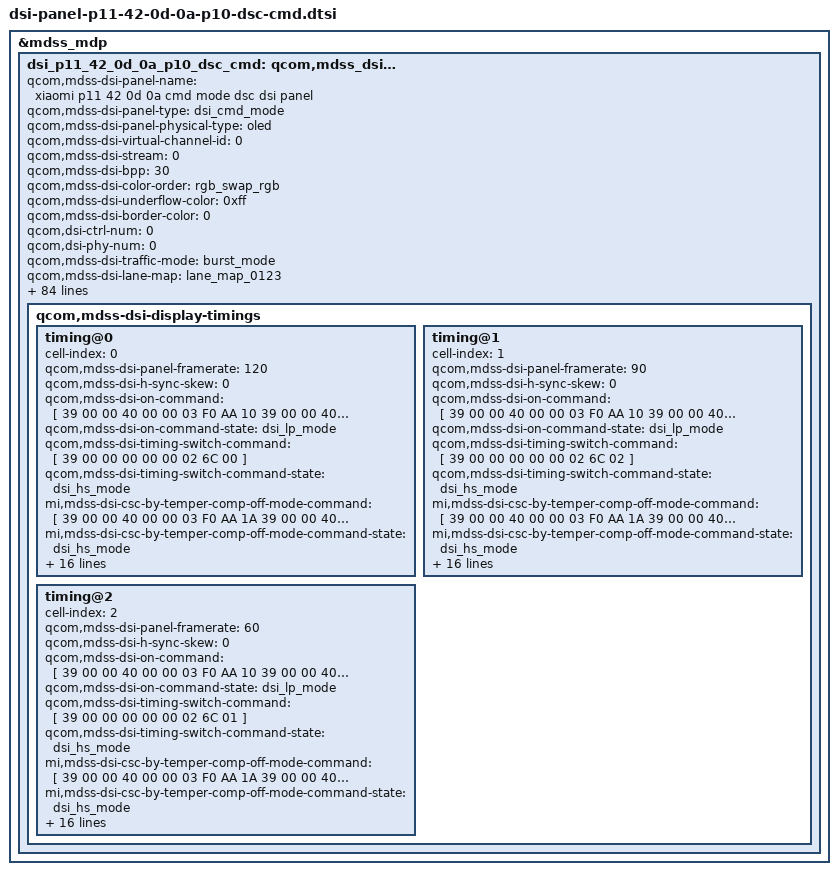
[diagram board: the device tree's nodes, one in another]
&mdss_mdp {
	dsi_p11_42_0d_0a_p10_dsc_cmd: qcom,mdss_dsi_p11_42_0d_0a_p10_dsc_cmd {
		qcom,mdss-dsi-panel-name = "xiaomi p11 42 0d 0a cmd mode dsc dsi panel";
		qcom,mdss-dsi-panel-type = "dsi_cmd_mode";
		qcom,mdss-dsi-panel-physical-type = "oled";
		qcom,mdss-dsi-virtual-channel-id = <0>;
		qcom,mdss-dsi-stream = <0>;
		qcom,mdss-dsi-bpp = <30>;
		qcom,mdss-dsi-color-order = "rgb_swap_rgb";
		qcom,mdss-dsi-underflow-color = <0xff>;
		qcom,mdss-dsi-border-color = <0>;
		qcom,dsi-ctrl-num = <0>;
		qcom,dsi-phy-num = <0>;
		qcom,mdss-dsi-traffic-mode = "burst_mode";
		qcom,mdss-dsi-lane-map = "lane_map_0123";
		qcom,mdss-dsi-bllp-eof-power-mode;
		qcom,mdss-dsi-bllp-power-mode;
		qcom,mdss-dsi-lane-0-state;
		qcom,mdss-dsi-lane-1-state;
		qcom,mdss-dsi-lane-2-state;
		qcom,mdss-dsi-lane-3-state;
		qcom,mdss-dsi-dma-trigger = "trigger_sw";
		qcom,mdss-dsi-mdp-trigger = "none";
		qcom,mdss-dsi-reset-sequence =<1 5>, <0 5>, <1 10>;
		qcom,mdss-pan-physical-width-dimension = <701>;
		qcom,mdss-pan-physical-height-dimension = <1521>;
		qcom,mdss-dsi-te-pin-select = <1>;
		qcom,mdss-dsi-wr-mem-start = <0x2c>;
		qcom,mdss-dsi-wr-mem-continue = <0x3c>;
		qcom,mdss-dsi-te-dcs-command = <1>;
		qcom,mdss-dsi-te-check-enable;
		qcom,mdss-dsi-te-using-te-pin;
		qcom,mdss-dsi-tx-eot-append;
		qcom,mdss-dsi-lp11-init;
		qcom,mdss-dsi-bl-inverted-dbv;
		qcom,mdss-dsi-panel-dimming-enabled;
		qcom,bl-update-flag = "delay_until_first_frame";
		qcom,mdss-dsi-panel-hdr-enabled;
		qcom,mdss-dsi-panel-hdr-color-primaries = <14500 15500 32000
			17000 15500 30000 8000 3000>;
		qcom,mdss-dsi-panel-peak-brightness = <32000000>;
		qcom,mdss-dsi-panel-blackness-level = <3230>;
		qcom,mdss-dsi-dma-schedule-line = <1>;
		qcom,mdss-dsi-dma-schedule-window = <50>;
		mi,panel-id = <0x00503131 0x50420D0A>;
		mi,panel-on-dimming-delay = <120>;

		/* IRQF_ONESHOT | IRQF_TRIGGER_LOW */
		mi,esd-err-irq-gpio = <&tlmm 87 0x2008>;
		mi,esd-err-irq-gpio-flag = <0x2008>;

		mi,mdss-dsi-panel-wp-read-command = [06 01 00 01 00 00 01 5C];
		mi,mdss-dsi-panel-wp-read-command-state = "dsi_hs_mode";
		mi,mdss-dsi-panel-wp-read-length = <8>;

		mi,mdss-dsi-panel-cell-id-read-command = [06 01 00 01 00 00 01 5A];
		mi,mdss-dsi-panel-cell-id-read-command-state = "dsi_hs_mode";
		mi,mdss-dsi-panel-cell-id-read-length = <14>;
		mi,max-brightness-clone = <16383>;
		mi,mdss-dsi-fac-bl-max-level = <6750>;
		mi,mdss-fac-brightness-max-level = <6750>;
		mi,flatmode-status-check-enabled;
		mi,mdss-dsi-panel-flatmode-status-offset-command = [
 			39 00 00 00 00 00 03 F0 AA 11
 		];
		mi,mdss-dsi-panel-flatmode-status-offset-command-state = "dsi_hs_mode";
		mi,mdss-dsi-panel-flatmode-status-command = [
				06 01 00 01 00 00 01 D5
		];
		mi,mdss-dsi-panel-flatmode-status-command-state = "dsi_hs_mode";
		mi,mdss-dsi-panel-flatmode-status-read-length = <1>;
		mi,mdss-dsi-panel-flatmode-on-status-value = <0x13>;

		mi,doze-hbm-dbv-level = <609>;
		mi,doze-lbm-dbv-level = <46>;
		mi,ddic-round-corner-enabled;
		qcom,mdss-disable-cesta-hw-sleep;

		qcom,mdss-dsi-display-timings {
			timing@0 {
				#include "dsi-panel-p11-42-0d-0a-p10-dsc-cmd-common.dtsi"
				cell-index = <0>;
				qcom,mdss-dsi-panel-framerate = <120>;
				qcom,mdss-dsi-h-sync-skew = <0>;

				qcom,mdss-dsi-on-command = [
					39 00 00 40 00 00 03 F0 AA 10
					39 00 00 40 00 00 0A B0 04 E7 01 21 12 04 84 04 E7
					39 00 00 40 00 00 16 B1 01 9F 00 11 00 21 00 01 9F 00 11 0A 21 00 01 9F 00 11 03 79 00
					39 00 00 40 00 00 16 B2 01 9F 00 11 00 21 03 01 9F 00 11 00 21 03 01 9F 00 11 00 21 03
					39 00 00 40 00 00 11 C1 04 00 00 00 04 00 00 00 04 00 00 00 04 00 00 00
					39 00 00 40 00 00 04 C3 53 44 00
					39 00 00 40 00 00 02 65 13
					39 00 00 40 00 00 02 C4 80
					39 00 00 40 00 00 09 C4 28 28 28 28 28 28 28 28
					39 00 00 40 00 00 02 65 0A
					39 00 00 40 00 00 07 C4 28 28 28 28 28 28
					39 00 00 40 00 00 06 C6 62 52 00 00 A0
					39 00 00 40 00 00 02 CF 09
					39 00 00 40 00 00 02 65 02
					39 00 00 40 00 00 02 CF 1C
					39 00 00 40 00 00 02 65 04
					39 00 00 40 00 00 03 CF 93 92
					39 00 00 40 00 00 02 65 09
					39 00 00 40 00 00 02 CF 5F
					39 00 00 40 00 00 02 65 0B
					39 00 00 40 00 00 03 CF FD 79
					39 00 00 40 00 00 02 B6 00
					39 00 00 40 00 00 02 BD 60
					39 00 00 40 00 00 14 D0 84 68 22 22 00 0F 12 12 66 66 20 00 05 14 14 55 55 50 00
					39 00 00 40 00 00 2A D1 00 35 0F 0F 0F 0F 47 00 00 4F 00 00 00 00 33 47 4F 00 00 00 00 29 11 11 11 11 2B 00 00 32 00 00 00 00 29 2A 33 00 00 00 00
					39 00 00 40 00 00 31 D3 00 05 00 0F 00 1E 00 2E 00 80 01 2E 02 61 05 4C 0A 29 13 E2 1A 5E 34 BC 3F FF 3F FF 3F FF 3F FF 1F 1F 1F 1F 1F 1F 1F 24 21 1F 1A 00 00 00 00 00
					39 00 00 40 00 00 31 D4 00 05 00 0F 00 1E 00 2E 00 80 01 2E 02 61 05 4C 0A 29 13 E2 1A 5E 34 BC 3F FF 3F FF 3F FF 3F FF 1F 1F 1F 1F 1F 1F 1F 24 21 1F 1A 00 00 00 00 00
					39 00 00 40 00 00 31 D5 00 05 00 0F 00 1E 00 2E 00 80 01 2E 02 61 05 4C 0A 29 13 E2 1A 5E 34 BC 3F FF 3F FF 3F FF 3F FF 1F 1F 1F 1F 1F 1F 1F 24 21 1F 1A 00 00 00 00 00
					39 00 00 40 00 00 31 D6 00 05 00 0F 00 1E 00 2E 00 80 01 2E 02 61 05 4C 0A 29 13 E2 1A 5E 34 BC 3F FF 3F FF 3F FF 3F FF 1F 1F 1F 1F 1F 1F 1F 24 21 1F 1A 00 00 00 00 00
					39 00 00 40 00 00 03 E7 40 46
					39 00 00 40 00 00 02 65 0D
					39 00 00 00 00 00 02 C8 01
					39 00 00 40 00 00 03 F0 AA 11
					39 00 00 40 00 00 1C D0 A1 2A 90 90 90 2A 90 90 90 01 3F 00 00 00 3F 10 10 10 3F 80 80 80 00 70 5F 20 81
					39 00 00 40 00 00 02 65 2A
					39 00 00 40 00 00 03 D0 17 60
					39 00 00 40 00 00 02 65 03
					39 00 00 40 00 00 04 C0 14 1E 20
					39 00 00 40 00 00 03 F0 AA 11
					39 00 00 40 00 00 02 65 01
					39 00 00 40 00 00 07 C3 34 BC 3F FF 01 6C
					39 00 00 40 00 00 02 65 07
					39 00 00 40 00 00 05 C3 56 45 32 65
					39 00 00 40 00 00 02 65 0B
					39 00 00 40 00 00 0D C3 FF BF 02 FF FF FF BC 92 8B 71 F7 04
					39 00 00 40 00 00 02 65 17
					39 00 00 40 00 00 05 C3 55 55 55 55
					39 00 00 40 00 00 02 65 1B
					39 00 00 40 00 00 0C C3 00 01 00 1C 38 57 76 9C C6 E1 00
					39 00 00 40 00 00 03 F0 AA 12
					39 00 00 40 00 00 05 B1 5F 5F 5F 13
					39 00 00 40 00 00 0C B2 44 55 44 44 55 44 44 55 44 44 05
					39 00 00 40 00 00 0F B3 06 10 06 10 06 10 06 10 06 10 06 10 06 10
					39 00 00 40 00 00 0F B5 03 80 03 00 03 80 03 00 03 80 03 00 03 80
					39 00 00 40 00 00 0F B6 06 C0 0E 40 06 C0 0E 40 06 C0 0E 40 06 C0
					39 00 00 40 00 00 0F B7 68 68 68 68 68 68 68 68 68 68 68 68 68 68
					39 00 00 40 00 00 1D B8 02 04 02 04 02 04 02 04 02 04 02 04 02 04 02 04 02 04 02 04 02 04 02 04 02 04 02 04
					39 00 00 40 00 00 09 B9 01 B6 01 B6 01 B6 01 B6
					39 00 00 40 00 00 02 65 08
					39 00 00 40 00 00 07 B9 01 52 01 52 01 52
					39 00 00 40 00 00 02 65 16
					39 00 00 40 00 00 07 B9 00 58 00 58 00 58
					39 00 00 40 00 00 02 65 24
					39 00 00 40 00 00 07 B9 00 44 00 44 00 44
					39 00 00 40 00 00 02 65 54
					39 00 00 40 00 00 03 B9 00 44
					39 00 00 40 00 00 04 BB 00 32 00
					39 00 00 40 00 00 02 65 05
					39 00 00 40 00 00 04 BB B3 B3 B3
					39 00 00 40 00 00 07 C7 FF 78 43 5A 33 33
					39 00 00 40 00 00 0D E9 00 00 00 00 00 00 00 00 00 00 00 00
					39 00 00 40 00 00 02 CF 03
					39 00 00 40 00 00 04 D1 04 00 11
					39 00 00 40 00 00 0B D2 0F 00 00 1A 00 1A 00 1A 00 1A
					39 00 00 40 00 00 03 D6 02 00
					39 00 00 40 00 00 02 C9 3C
					39 00 00 00 00 00 2B C4 00 00 02 00 00 0F 00 00 02 00 00 0F 00 00 02 00 00 0F 00 00 02 00 00 0F 00 00 02 00 00 0F 00 00 02 00 00 0F 00 00 02 00 00 0F
					39 00 00 40 00 00 03 F0 AA 13
					39 00 00 40 00 00 11 BD 20 11 0A 04 04 0A 11 20 2A 15 15 2A 2A 2A 15 15
					39 00 00 40 00 00 0A C2 01 34 BC 34 BC 34 BC 34 BC
					39 00 00 40 00 00 07 C3 21 43 65 21 43 65
					39 00 00 40 00 00 02 65 01
					39 00 00 40 00 00 02 EF E0
					39 00 00 40 00 00 02 65 03
					39 00 00 40 00 00 02 EF E0
					39 00 00 40 00 00 0E C8 10 C0 15 3F FF 3F FF 3F FF 00 00 00 00
					39 00 00 40 00 00 19 C9 77 77 77 77 77 77 77 77 01 02 03 04 05 06 07 08 09 0A 0B 0C 0D 0D 0D 0D
					39 00 00 40 00 00 21 CA 00 05 00 0F 00 1E 00 2E 00 80 01 2E 02 61 05 4C 0A 29 13 E2 1A 5E 34 BC 3F FF 3F FF 3F FF 3F FF
					39 00 00 40 00 00 21 CB 0A 00 09 00 08 80 06 80 05 80 04 80 01 F0 00 10 00 10 00 10 00 10 00 10 00 10 00 10 00 10 00 10
					39 00 00 40 00 00 21 CC 03 80 03 80 03 80 03 80 03 80 03 80 03 80 03 80 03 80 03 80 03 80 03 80 03 80 03 80 03 80 03 80
					39 00 00 40 00 00 21 CD 09 40 09 40 09 40 09 40 09 40 09 40 06 C0 06 C0 06 C0 06 C0 06 C0 01 C0 01 C0 01 C0 01 C0 01 C0
					39 00 00 40 00 00 0E D0 10 80 00 3F FF 3F FF 3F FF 01 01 01 01
					39 00 00 40 00 00 19 D1 77 77 77 77 77 77 77 77 0E 0F 10 11 12 13 14 15 16 17 18 19 1A 1A 1A 1A
					39 00 00 40 00 00 21 D2 00 05 00 0F 00 1E 00 2E 00 80 01 2E 02 61 05 4C 0A 29 13 E2 1A 5E 34 BC 3F FF 3F FF 3F FF 3F FF
					39 00 00 40 00 00 21 D3 14 00 12 00 11 00 0D 00 0B 00 09 00 03 E0 00 20 00 20 00 20 00 20 00 20 00 20 00 20 00 20 00 20
					39 00 00 40 00 00 21 D4 03 80 03 80 03 80 03 80 03 80 03 80 03 80 03 80 03 80 03 80 03 80 03 80 03 80 03 80 03 80 03 80
					39 00 00 40 00 00 21 D5 09 40 09 40 09 40 09 40 09 40 09 40 06 C0 06 C0 06 C0 06 C0 06 C0 01 C0 01 C0 01 C0 01 C0 01 C0
					39 00 00 40 00 00 0E E0 10 80 00 3F FF 3F FF 3F FF 00 00 00 00
					39 00 00 40 00 00 19 E1 77 77 77 77 77 77 77 77 1E 1F 20 21 22 23 24 25 26 27 28 29 2A 2A 2A 2A
					39 00 00 40 00 00 21 E2 00 05 00 0F 00 1E 00 2E 00 80 01 2E 02 61 05 4C 0A 29 13 E2 1A 5E 34 BC 3F FF 3F FF 3F FF 3F FF
					39 00 00 40 00 00 21 E3 0D 58 0C 00 0B 54 08 AC 07 54 06 00 02 94 00 10 00 10 00 10 00 10 00 10 00 10 00 10 00 10 00 10
					39 00 00 40 00 00 21 E4 03 80 03 80 03 80 03 80 03 80 03 80 03 80 03 80 03 80 03 80 03 80 03 80 03 80 03 80 03 80 03 80
					39 00 00 40 00 00 21 E5 09 40 09 40 09 40 09 40 09 40 09 40 06 C0 06 C0 06 C0 06 C0 06 C0 01 C0 01 C0 01 C0 01 C0 01 C0
					39 00 00 40 00 00 0F DD 00 04 04 04 00 00 04 04 00 00 04 04 00 00
					39 00 00 00 00 00 0D DE 00 00 80 1B 00 00 80 1C 00 00 80 1D
					39 00 00 40 00 00 03 F0 AA 13
					39 00 00 40 00 00 1F CE 87 3E 43 33 00 BA 00 BA 00 BA 88 40 44 2D 01 37 01 37 01 37 89 64 62 49 02 6E 02 6E 02 6E
					39 00 00 40 00 00 1F D6 87 3E 43 33 00 BA 00 BA 00 BA 88 40 44 2D 01 37 01 37 01 37 89 64 62 49 02 6E 02 6E 02 6E
					39 00 00 40 00 00 1F E6 87 3E 43 33 00 BA 00 BA 00 BA 88 40 44 2D 01 37 01 37 01 37 89 64 62 49 02 6E 02 6E 02 6E
					39 00 00 40 00 00 1F EE 87 3E 43 33 00 BA 00 BA 00 BA 88 40 44 2D 01 37 01 37 01 37 89 64 62 49 02 6E 02 6E 02 6E
					39 00 00 40 00 00 03 F0 AA 14
					39 00 00 40 00 00 0B B2 3F 37 00 00 00 00 00 00 00 00
					39 00 00 40 00 00 17 B5 00 00 00 00 1B 1B 1B 1B 1B 1B 1B 1B 0B 02 00 00 00 00 00 00 00 00
					39 00 00 40 00 00 0E BC A0 00 00 0D 13 1B 63 1B 63 1B 63 1B 63
					39 00 00 40 00 00 0E BF 90 10 00 0D 22 00 28 00 28 00 28 00 28
					39 00 00 40 00 00 07 B9 00 00 0D 00 00 00
					39 00 00 40 00 00 03 F0 AA 14
					39 00 00 40 00 00 18 B0 00 00 00 70 00 00 00 10 10 10 10 10 10 10 10 10 10 10 10 10 10 10 10
					39 00 00 40 00 00 02 65 17
					39 00 00 40 00 00 0D B0 10 10 10 10 10 10 10 10 10 10 10 10
					39 00 00 40 00 00 03 F0 AA 15
					39 00 00 40 00 00 03 B0 0F 00
					39 00 00 40 00 00 0B B1 A6 25 A6 45 A6 65 A6 25 00 00
					39 00 00 40 00 00 13 B2 37 03 00 77 33 00 70 30 00 05 31 30 55 11 00 50 10 00
					39 00 00 40 00 00 13 B4 26 44 00 66 44 00 60 40 00 41 25 00 11 55 00 10 50 00
					39 00 00 40 00 00 13 B5 26 24 00 66 44 00 60 40 00 26 00 00 66 00 00 60 00 00
					39 00 00 40 00 00 13 B6 26 44 00 66 44 00 60 40 00 44 22 00 44 22 00 40 20 00
					39 00 00 40 00 00 13 B7 26 44 00 66 44 00 60 40 00 44 22 00 44 22 00 40 20 00
					39 00 00 40 00 00 09 BC 08 01 08 01 08 01 08 01
					39 00 00 40 00 00 05 BD 00 00 00 00
					39 00 00 40 00 00 0C BE 22 00 11 11 11 22 44 44 44 44 00
					39 00 00 40 00 00 02 C4 01
					39 00 00 40 00 00 11 C5 08 5A 00 00 08 5A 00 00 08 5A 00 00 08 5A 00 00
					39 00 00 40 00 00 02 65 01
					39 00 00 40 00 00 02 C4 02
					39 00 00 40 00 00 09 D2 00 01 06 C6 07 F3 0E B8
					39 00 00 40 00 00 0E E0 13 01 02 40 00 00 00 08 00 E4 E4 24 24
					39 00 00 40 00 00 02 65 10
					39 00 00 40 00 00 02 C5 01
					39 00 00 40 00 00 03 F0 AA 15
					39 00 00 00 00 00 05 BF 00 49 D9 30
					39 00 00 40 00 00 03 F0 AA 16
					39 00 00 40 00 00 05 B0 0C 37 34 37
					39 00 00 40 00 00 05 B1 00 37 35 37
					39 00 00 40 00 00 05 B2 23 37 22 37
					39 00 00 40 00 00 05 B3 35 37 0E 37
					39 00 00 40 00 00 05 B4 0F 37 10 37
					39 00 00 40 00 00 06 B5 11 37 37 37 37
					39 00 00 40 00 00 05 B6 0C 37 34 37
					39 00 00 40 00 00 05 B7 00 37 35 37
					39 00 00 40 00 00 05 B8 23 37 22 37
					39 00 00 40 00 00 05 B9 35 37 0E 37
					39 00 00 40 00 00 05 BA 0F 37 10 37
					39 00 00 40 00 00 06 BB 11 37 37 37 37
					39 00 00 40 00 00 0D D1 00 00 00 00 00 00 00 00 00 00 00 00
					39 00 00 40 00 00 02 65 0C
					39 00 00 40 00 00 04 D1 03 03 00
					39 00 00 40 00 00 03 F0 AA 16
					39 00 00 40 00 00 02 E1 70
					39 00 00 40 00 00 02 65 06
					39 00 00 40 00 00 04 E1 00 00 00
					39 00 00 40 00 00 02 65 0F
					39 00 00 40 00 00 05 E1 00 00 00 00
					39 00 00 40 00 00 02 65 20
					39 00 00 40 00 00 05 E2 E0 60 C0 E0
					39 00 00 40 00 00 02 65 08
					39 00 00 40 00 00 02 D2 10
					39 00 00 40 00 00 02 65 13
					39 00 00 40 00 00 0F D2 0A 40 0A 40 0A 40 0A 40 0A 40 0A 40 0A 40
					39 00 00 40 00 00 02 65 21
					39 00 00 40 00 00 0F D2 0A 70 0D F0 14 F0 14 F0 0A 70 0A 70 0A 70
					39 00 00 40 00 00 03 F0 AA 17
					39 00 00 40 00 00 02 B0 B0
					39 00 00 40 00 00 02 B4 08
					39 00 00 40 00 00 07 C0 21 43 65 21 43 65
					39 00 00 40 00 00 02 C2 80
					39 00 00 40 00 00 13 B2 00 40 00 00 40 00 00 20 20 00 40 00 00 40 00 00 20 20
					39 00 00 40 00 00 02 65 1A
					39 00 00 40 00 00 0D B2 20 00 00 20 00 00 20 00 00 20 00 00
					39 00 00 40 00 00 02 65 26
					39 00 00 40 00 00 0D B2 10 F0 10 10 F0 10 20 F0 F0 20 F0 F0
					39 00 00 40 00 00 02 65 03
					39 00 00 40 00 00 02 B1 12
					39 00 00 40 00 00 02 65 05
					39 00 00 40 00 00 05 B4 02 04 08 10
					39 00 00 40 00 00 02 65 11
					39 00 00 40 00 00 05 B4 03 06 0C 18
					39 00 00 40 00 00 25 B3 A0 A0 80 A0 A0 80 80 A0 A0 80 C0 80 00 40 00 00 20 20 20 20 00 20 20 00 00 20 20 00 40 00 00 40 00 00 20 20
					39 00 00 00 00 00 03 C3 88 88
					39 00 00 40 00 00 03 F0 AA 19
					39 00 00 40 00 00 06 D0 01 00 07 00 00
					39 00 00 40 00 00 0D D1 43 33 34 43 34 44 34 43 33 33 33 33
					39 00 00 40 00 00 09 D2 88 88 88 88 88 88 88 88
					39 00 00 40 00 00 03 D3 80 80
					39 00 00 40 00 00 31 D4 00 00 00 00 00 00 00 00 00 00 00 00 00 00 00 00 00 00 00 00 00 00 00 00 00 00 00 00 00 00 00 00 05 0A 0A 0A 0A 1E 1E 1E 1E 1E 1E 28 28 28 28 28
					39 00 00 40 00 00 31 D5 00 00 00 00 00 00 00 00 00 00 00 00 00 00 00 00 00 00 00 00 00 00 00 00 00 00 00 00 00 00 00 00 00 00 00 00 00 00 00 00 00 00 00 00 00 00 00 00
					39 00 00 40 00 00 31 D6 00 00 00 00 00 00 00 00 00 00 00 00 00 00 00 00 00 00 00 00 00 00 00 00 00 00 00 00 00 00 00 00 FE FB FB FB FB EC EC EC EC EC EC EC EC EC EC EC
					39 00 00 40 00 00 31 D7 00 00 00 00 00 00 00 00 00 00 00 00 00 00 00 00 00 00 00 00 00 00 00 00 00 00 00 00 00 00 00 00 00 00 00 00 00 00 00 00 00 00 00 00 00 00 00 00
					39 00 00 40 00 00 31 D8 00 00 00 00 00 00 00 00 00 00 00 00 00 00 00 00 00 00 00 00 00 00 00 00 00 00 00 00 00 00 00 00 00 00 00 00 00 F6 F6 F6 F6 F6 F6 F6 F6 F6 F6 F6
					39 00 00 40 00 00 31 D9 00 00 00 00 00 00 00 00 00 00 00 00 00 00 00 00 00 00 00 00 00 00 00 00 00 00 00 00 00 00 00 00 00 00 00 00 00 00 00 00 00 00 00 00 00 00 00 00
					39 00 00 40 00 00 31 DD 00 00 00 00 00 00 00 00 00 00 00 00 00 00 00 00 00 00 00 00 00 00 00 00 00 00 00 00 00 00 00 00 00 00 00 00 00 00 00 00 00 00 00 00 00 00 00 00
					39 00 00 40 00 00 31 DE 00 00 00 00 00 00 00 00 00 00 00 00 00 00 00 00 00 00 00 00 00 00 00 00 00 00 00 00 00 00 00 00 00 00 00 00 00 00 00 00 00 00 00 00 00 00 00 00
					39 00 00 00 00 00 19 DF 00 00 00 00 00 00 00 00 00 00 00 00 00 00 00 00 00 00 00 00 00 00 00 00
					39 00 00 40 00 00 03 F0 AA 19
					39 00 00 40 00 00 02 65 01
					39 00 00 40 00 00 09 C0 86 0C 01 3F FF 00 80 08
					39 00 00 40 00 00 05 C1 55 55 55 55
					39 00 00 40 00 00 13 C2 00 0F 00 0F 00 0F 02 61 02 61 02 61 1A 5E 1A 5E 1A 5E
					39 00 00 40 00 00 25 C3 00 05 00 0F 00 1E 00 2E 00 80 01 2E 02 61 05 4C 0A 29 13 E2 1A 5E 34 BC 00 19 00 2B 00 3E 00 61 00 8F 00 CE
					39 00 00 40 00 00 02 C5 00
					39 00 00 40 00 00 03 F0 AA 19
					39 00 00 40 00 00 04 C9 00 00 00
					39 00 00 40 00 00 02 65 03
					39 00 00 40 00 00 04 C9 03 D1 40
					39 00 00 40 00 00 03 F0 AA 1A
					39 00 00 40 00 00 02 65 01
					39 00 00 40 00 00 03 B0 00 00
					39 00 00 40 00 00 0F B1 0C 70 00 84 84 84 04 07 00 00 00 00 00 00
					39 00 00 40 00 00 03 F0 AA 1A
					39 00 00 40 00 00 0F B9 00 00 00 00 00 00 00 00 00 00 00 00 00 00
					39 00 00 40 00 00 11 B8 01 02 03 04 05 06 07 00 00 00 00 00 00 00 00 00
					39 00 00 40 00 00 21 BA 00 05 00 0F 00 1E 00 2E 00 80 01 2E 02 61 05 4C 0A 29 13 E2 1A 5E 34 BC 3F FF 3F FF 3F FF 3F FF
					39 00 00 40 00 00 21 BB 00 05 00 0F 00 1E 00 2E 00 80 01 2E 02 61 05 4C 0A 29 13 E2 1A 5E 34 BC 3F FF 3F FF 3F FF 3F FF
					39 00 00 00 00 00 07 B2 42 53 66 76 87 77
					39 00 00 40 00 00 03 F0 AA 1E
					39 00 00 40 00 00 04 C8 0A 45 10
					39 00 00 40 00 00 02 65 20
					39 00 00 40 00 00 21 CA 00 44 00 44 00 44 00 44 00 44 00 44 00 44 00 44 00 44 00 44 00 76 01 E8 01 E8 01 E8 01 E8 01 E8
					39 00 00 40 00 00 02 65 40
					39 00 00 40 00 00 21 CA 00 30 00 30 00 30 00 30 00 30 00 30 00 30 00 30 00 30 00 30 00 62 01 D4 01 D4 01 D4 01 D4 01 D4
					39 00 00 40 00 00 02 65 20
					39 00 00 40 00 00 21 CE 00 58 00 58 00 58 00 58 00 58 00 58 00 58 00 58 00 58 00 58 00 8A 01 FC 01 FC 01 FC 01 FC 01 FC
					39 00 00 40 00 00 02 65 40
					39 00 00 40 00 00 21 CE 00 44 00 44 00 44 00 44 00 44 00 44 00 44 00 44 00 44 00 44 00 76 01 E8 01 E8 01 E8 01 E8 01 E8
					39 00 00 40 00 00 02 65 20
					39 00 00 40 00 00 21 D2 00 44 00 44 00 44 00 44 00 44 00 44 00 44 00 44 00 44 00 44 00 76 01 E8 01 E8 01 E8 01 E8 01 E8
					39 00 00 40 00 00 02 65 40
					39 00 00 40 00 00 21 D2 00 30 00 30 00 30 00 30 00 30 00 30 00 30 00 30 00 30 00 30 00 62 01 D4 01 D4 01 D4 01 D4 01 D4
					39 00 00 40 00 00 21 C9 00 05 00 0F 00 1E 00 2E 00 80 01 2E 02 61 05 4C 0A 29 13 E2 1A 5E 34 BC 3F FF 3F FF 3F FF 3F FF
					39 00 00 40 00 00 21 CD 00 05 00 0F 00 1E 00 2E 00 80 01 2E 02 61 05 4C 0A 29 13 E2 1A 5E 34 BC 3F FF 3F FF 3F FF 3F FF
					39 00 00 40 00 00 21 D1 00 05 00 0F 00 1E 00 2E 00 80 01 2E 02 61 05 4C 0A 29 13 E2 1A 5E 34 BC 3F FF 3F FF 3F FF 3F FF
					39 00 00 00 00 00 21 D5 00 05 00 0F 00 1E 00 2E 00 80 01 2E 02 61 05 4C 0A 29 13 E2 1A 5E 34 BC 3F FF 3F FF 3F FF 3F FF
					39 00 00 40 00 00 03 F0 AA 10
					39 00 00 40 00 00 02 65 04
					39 00 00 40 00 00 04 EA 48 CB 01
					39 00 00 40 00 00 02 65 0D
					39 00 00 40 00 00 04 EA 0C 00 01
					39 00 00 40 00 00 02 65 10
					39 00 00 40 00 00 04 EA 0C 80 01
					39 00 00 40 00 00 02 65 13
					39 00 00 40 00 00 04 EA C8 AE 01
					39 00 00 40 00 00 02 65 16
					39 00 00 40 00 00 04 EA 64 C1 01
					39 00 00 40 00 00 02 65 19
					39 00 00 40 00 00 04 EA 98 A5 01
					39 00 00 40 00 00 02 65 28
					39 00 00 40 00 00 04 EA 0C 00 00
					39 00 00 40 00 00 02 65 0A
					39 00 00 40 00 00 02 EB 10
					39 00 00 40 00 00 03 F0 AA 10
					39 00 00 40 00 00 02 65 01
					39 00 00 40 00 00 02 CF 87
					39 00 00 40 00 00 02 59 09
					39 00 00 40 00 00 03 F0 AA 10
					39 00 00 40 00 00 04 EB 00 00 30
					39 00 00 40 00 00 05 EA 0F 41 00 08
					39 00 00 40 00 00 03 F0 AA 11
					39 00 00 40 00 00 02 C3 00
					39 00 00 40 00 00 03 F0 AA 18
					39 00 00 40 00 00 02 B0 80
					39 00 00 40 00 00 03 F0 AA 19
					39 00 00 40 00 00 02 D0 01
					39 00 00 40 00 00 03 F0 AA 19
					39 00 00 40 00 00 02 C0 E0
					39 00 00 40 00 00 03 F0 AA 1A
					39 00 00 40 00 00 02 B0 01
					39 00 00 40 00 00 03 FF 5A 83
					39 00 00 40 00 00 02 65 0B
					39 00 00 40 00 00 02 F8 05
					39 00 00 40 00 00 03 FF 5A 81
					39 00 00 40 00 00 02 65 03
					39 00 00 40 00 00 02 F3 04
					39 00 00 40 00 00 02 65 05
					39 00 00 40 00 00 02 F3 48
					39 00 00 40 00 00 03 FF 5A 80
					39 00 00 40 00 00 02 65 0E
					39 00 00 40 00 00 02 F9 A1
					39 00 00 40 00 00 02 03 01
					39 00 00 40 00 00 02 35 00
					39 00 00 40 00 00 02 53 20
					39 00 00 40 00 00 03 51 00 00
					39 00 00 40 00 00 02 6B 00
					39 00 00 40 00 00 02 6F 02
					39 00 00 40 00 00 02 6C 00
					39 00 00 40 00 00 02 6D 00
					39 00 00 40 00 00 5F 70 12 00 00 AB 30 80 09 CE 04 84 00 0A 02 42 02 42 02 00 01 19 00 20 01 A0 00 08 00 01 00 E4 09 8D 18 00 11 00 07 10 20 00 06 0F 0F 33 0E 1C 2A 38 46 54 62 69 70 77 79 7B 7D 7E 02 02 22 00 2A 40 2A BE 3A FC 3A FA 3A F8 3B 38 3B 78 3B B6 4B B6 4B F4 4B F4 6C 34 84 74 00 00 00 00 00 00
					39 00 00 40 00 00 02 72 00
					39 00 00 40 00 00 03 F0 AA 00
					39 00 00 40 00 00 03 FF 5A 00
					39 00 00 40 00 00 03 FF 5A 80
					39 00 00 40 00 00 02 65 0E
					39 00 00 40 00 00 02 F9 A1
					39 00 00 00 78 00 01 11
					39 00 00 00 00 00 01 29
					//GIR & Slice ACL ON
					39 00 00 40 00 00 02 A4 01
					39 00 00 40 00 00 03 F0 AA 11
					39 00 00 40 00 00 02 D5 13
					39 00 00 40 00 00 02 C3 31
					39 00 00 40 00 00 02 A4 00
					39 00 00 00 00 00 02 A6 01
					//end
					//OSC sync to mipi clk begin
					39 00 00 40 00 00 03 F0 AA 14
					39 00 00 40 00 00 02 C1 0B
					39 00 00 40 00 00 20 C3 01 21 20 03 AD 03 AD 03 AD 03 AD 03 AD 03 AD 03 AD 00 C7 00 C7 00 C7 00 C7 00 31 00 31 00 31
					//end
					39 00 00 40 00 00 03 F0 AA 1E
					39 00 00 40 00 00 02 65 02
					39 00 00 00 00 00 02 C8 10
					39 00 00 40 00 00 03 F0 AA 10
					39 00 00 40 00 00 02 65 04
					39 00 00 40 00 00 02 B0 02
					//AOD timing optimization
					39 00 00 40 00 00 03 F0 AA 12
					39 00 00 40 00 00 02 65 02
					39 00 00 40 00 00 02 D1 00
					//MIPI Error Gating Set For ESD
					//check MIPI HS timeout
					39 00 00 40 00 00 03 F0 AA 10
					39 00 00 40 00 00 02 65 0B
					39 00 00 40 00 00 03 CF DD 79
					39 00 00 40 00 00 03 FF 5A 00
					39 00 00 00 00 00 03 F0 AA 00
					//AOD ISOP/IGOP/Pump clk
					39 00 00 40 00 00 03 F0 AA 10
					39 00 00 40 00 00 02 65 0A
					39 00 00 40 00 00 07 C4 00 00 00 00 00 00
					39 00 00 40 00 00 02 65 11
					39 00 00 40 00 00 02 C4 00
					39 00 00 40 00 00 03 F0 AA 12
					39 00 00 40 00 00 0C B2 75 35 77 75 35 77 75 35 77 57 05
					39 00 00 00 00 00 03 F0 AA 00
					//MIPI ULPS error ESD off
					39 00 00 40 00 00 03 F0 AA 10
					39 00 00 40 00 00 02 65 09
					39 00 00 40 00 00 02 CF 5B
					39 00 00 00 00 00 03 F0 AA 00
		          ];
				qcom,mdss-dsi-on-command-state = "dsi_lp_mode";
				qcom,mdss-dsi-timing-switch-command = [
					//120hz
					39 00 00 00 00 00 02 6C 00
				];
				qcom,mdss-dsi-timing-switch-command-state = "dsi_hs_mode";
				mi,mdss-dsi-csc-by-temper-comp-off-mode-command = [
					39 00 00 40 00 00 03 F0 AA 1A
					39 00 00 40 00 00 02 B0 01
					39 00 00 00 00 00 02 6B 00
					39 00 00 00 00 00 03 F0 AA 00
				];
				mi,mdss-dsi-csc-by-temper-comp-off-mode-command-state = "dsi_hs_mode";
				mi,mdss-dsi-csc-by-temper-comp-32-36-mode-command = [
					39 00 00 40 00 00 03 F0 AA 1A
					39 00 00 40 00 00 02 B0 01
					39 00 00 00 00 00 02 6B 01
					39 00 00 00 00 00 03 F0 AA 00
				];
				mi,mdss-dsi-csc-by-temper-comp-32-36-mode-command-state = "dsi_hs_mode";
				mi,mdss-dsi-csc-by-temper-comp-36-40-mode-command = [
					39 00 00 40 00 00 03 F0 AA 1A
					39 00 00 40 00 00 02 B0 01
					39 00 00 00 00 00 02 6B 02
					39 00 00 00 00 00 03 F0 AA 00
				];
				mi,mdss-dsi-csc-by-temper-comp-36-40-mode-command-state = "dsi_hs_mode";
				mi,mdss-dsi-csc-by-temper-comp-40-mode-command = [
					39 00 00 40 00 00 03 F0 AA 1A
					39 00 00 40 00 00 02 B0 01
					39 00 00 00 00 00 02 6B 04
					39 00 00 00 00 00 03 F0 AA 00
				];
				mi,mdss-dsi-csc-by-temper-comp-40-mode-command-state = "dsi_hs_mode";
				mi,mdss-dsi-csc-by-temper-comp-45-mode-command = [
					39 00 00 40 00 00 03 F0 AA 1A
					39 00 00 40 00 00 02 B0 01
					39 00 00 00 00 00 02 6B 06
					39 00 00 00 00 00 03 F0 AA 00
				];
				mi,mdss-dsi-csc-by-temper-comp-45-mode-command-state = "dsi_hs_mode";
			};
			timing@1 {
				#include "dsi-panel-p11-42-0d-0a-p10-dsc-cmd-common.dtsi"
				cell-index = <1>;
				qcom,mdss-dsi-panel-framerate = <90>;
				qcom,mdss-dsi-h-sync-skew = <0>;
				qcom,mdss-dsi-on-command = [
					39 00 00 40 00 00 03 F0 AA 10
					39 00 00 40 00 00 0A B0 04 E7 01 21 12 04 84 04 E7
					39 00 00 40 00 00 16 B1 01 9F 00 11 00 21 00 01 9F 00 11 0A 21 00 01 9F 00 11 03 79 00
					39 00 00 40 00 00 16 B2 01 9F 00 11 00 21 03 01 9F 00 11 00 21 03 01 9F 00 11 00 21 03
					39 00 00 40 00 00 11 C1 04 00 00 00 04 00 00 00 04 00 00 00 04 00 00 00
					39 00 00 40 00 00 04 C3 53 44 00
					39 00 00 40 00 00 02 65 13
					39 00 00 40 00 00 02 C4 80
					39 00 00 40 00 00 09 C4 28 28 28 28 28 28 28 28
					39 00 00 40 00 00 02 65 0A
					39 00 00 40 00 00 07 C4 28 28 28 28 28 28
					39 00 00 40 00 00 06 C6 62 52 00 00 A0
					39 00 00 40 00 00 02 CF 09
					39 00 00 40 00 00 02 65 02
					39 00 00 40 00 00 02 CF 1C
					39 00 00 40 00 00 02 65 04
					39 00 00 40 00 00 03 CF 93 92
					39 00 00 40 00 00 02 65 09
					39 00 00 40 00 00 02 CF 5F
					39 00 00 40 00 00 02 65 0B
					39 00 00 40 00 00 03 CF FD 79
					39 00 00 40 00 00 02 B6 00
					39 00 00 40 00 00 02 BD 60
					39 00 00 40 00 00 14 D0 84 68 22 22 00 0F 12 12 66 66 20 00 05 14 14 55 55 50 00
					39 00 00 40 00 00 2A D1 00 35 0F 0F 0F 0F 47 00 00 4F 00 00 00 00 33 47 4F 00 00 00 00 29 11 11 11 11 2B 00 00 32 00 00 00 00 29 2A 33 00 00 00 00
					39 00 00 40 00 00 31 D3 00 05 00 0F 00 1E 00 2E 00 80 01 2E 02 61 05 4C 0A 29 13 E2 1A 5E 34 BC 3F FF 3F FF 3F FF 3F FF 1F 1F 1F 1F 1F 1F 1F 24 21 1F 1A 00 00 00 00 00
					39 00 00 40 00 00 31 D4 00 05 00 0F 00 1E 00 2E 00 80 01 2E 02 61 05 4C 0A 29 13 E2 1A 5E 34 BC 3F FF 3F FF 3F FF 3F FF 1F 1F 1F 1F 1F 1F 1F 24 21 1F 1A 00 00 00 00 00
					39 00 00 40 00 00 31 D5 00 05 00 0F 00 1E 00 2E 00 80 01 2E 02 61 05 4C 0A 29 13 E2 1A 5E 34 BC 3F FF 3F FF 3F FF 3F FF 1F 1F 1F 1F 1F 1F 1F 24 21 1F 1A 00 00 00 00 00
					39 00 00 40 00 00 31 D6 00 05 00 0F 00 1E 00 2E 00 80 01 2E 02 61 05 4C 0A 29 13 E2 1A 5E 34 BC 3F FF 3F FF 3F FF 3F FF 1F 1F 1F 1F 1F 1F 1F 24 21 1F 1A 00 00 00 00 00
					39 00 00 40 00 00 03 E7 40 46
					39 00 00 40 00 00 02 65 0D
					39 00 00 00 00 00 02 C8 01
					39 00 00 40 00 00 03 F0 AA 11
					39 00 00 40 00 00 1C D0 A1 2A 90 90 90 2A 90 90 90 01 3F 00 00 00 3F 10 10 10 3F 80 80 80 00 70 5F 20 81
					39 00 00 40 00 00 02 65 2A
					39 00 00 40 00 00 03 D0 17 60
					39 00 00 40 00 00 02 65 03
					39 00 00 40 00 00 04 C0 14 1E 20
					39 00 00 40 00 00 03 F0 AA 11
					39 00 00 40 00 00 02 65 01
					39 00 00 40 00 00 07 C3 34 BC 3F FF 01 6C
					39 00 00 40 00 00 02 65 07
					39 00 00 40 00 00 05 C3 56 45 32 65
					39 00 00 40 00 00 02 65 0B
					39 00 00 40 00 00 0D C3 FF BF 02 FF FF FF BC 92 8B 71 F7 04
					39 00 00 40 00 00 02 65 17
					39 00 00 40 00 00 05 C3 55 55 55 55
					39 00 00 40 00 00 02 65 1B
					39 00 00 40 00 00 0C C3 00 01 00 1C 38 57 76 9C C6 E1 00
					39 00 00 40 00 00 03 F0 AA 12
					39 00 00 40 00 00 05 B1 5F 5F 5F 13
					39 00 00 40 00 00 0C B2 44 55 44 44 55 44 44 55 44 44 05
					39 00 00 40 00 00 0F B3 06 10 06 10 06 10 06 10 06 10 06 10 06 10
					39 00 00 40 00 00 0F B5 03 80 03 00 03 80 03 00 03 80 03 00 03 80
					39 00 00 40 00 00 0F B6 06 C0 0E 40 06 C0 0E 40 06 C0 0E 40 06 C0
					39 00 00 40 00 00 0F B7 68 68 68 68 68 68 68 68 68 68 68 68 68 68
					39 00 00 40 00 00 1D B8 02 04 02 04 02 04 02 04 02 04 02 04 02 04 02 04 02 04 02 04 02 04 02 04 02 04 02 04
					39 00 00 40 00 00 09 B9 01 B6 01 B6 01 B6 01 B6
					39 00 00 40 00 00 02 65 08
					39 00 00 40 00 00 07 B9 01 52 01 52 01 52
					39 00 00 40 00 00 02 65 16
					39 00 00 40 00 00 07 B9 00 58 00 58 00 58
					39 00 00 40 00 00 02 65 24
					39 00 00 40 00 00 07 B9 00 44 00 44 00 44
					39 00 00 40 00 00 02 65 54
					39 00 00 40 00 00 03 B9 00 44
					39 00 00 40 00 00 04 BB 00 32 00
					39 00 00 40 00 00 02 65 05
					39 00 00 40 00 00 04 BB B3 B3 B3
					39 00 00 40 00 00 07 C7 FF 78 43 5A 33 33
					39 00 00 40 00 00 0D E9 00 00 00 00 00 00 00 00 00 00 00 00
					39 00 00 40 00 00 02 CF 03
					39 00 00 40 00 00 04 D1 04 00 11
					39 00 00 40 00 00 0B D2 0F 00 00 1A 00 1A 00 1A 00 1A
					39 00 00 40 00 00 03 D6 02 00
					39 00 00 40 00 00 02 C9 3C
					39 00 00 00 00 00 2B C4 00 00 02 00 00 0F 00 00 02 00 00 0F 00 00 02 00 00 0F 00 00 02 00 00 0F 00 00 02 00 00 0F 00 00 02 00 00 0F 00 00 02 00 00 0F
					39 00 00 40 00 00 03 F0 AA 13
					39 00 00 40 00 00 11 BD 20 11 0A 04 04 0A 11 20 2A 15 15 2A 2A 2A 15 15
					39 00 00 40 00 00 0A C2 01 34 BC 34 BC 34 BC 34 BC
					39 00 00 40 00 00 07 C3 21 43 65 21 43 65
					39 00 00 40 00 00 02 65 01
					39 00 00 40 00 00 02 EF E0
					39 00 00 40 00 00 02 65 03
					39 00 00 40 00 00 02 EF E0
					39 00 00 40 00 00 0E C8 10 C0 15 3F FF 3F FF 3F FF 00 00 00 00
					39 00 00 40 00 00 19 C9 77 77 77 77 77 77 77 77 01 02 03 04 05 06 07 08 09 0A 0B 0C 0D 0D 0D 0D
					39 00 00 40 00 00 21 CA 00 05 00 0F 00 1E 00 2E 00 80 01 2E 02 61 05 4C 0A 29 13 E2 1A 5E 34 BC 3F FF 3F FF 3F FF 3F FF
					39 00 00 40 00 00 21 CB 0A 00 09 00 08 80 06 80 05 80 04 80 01 F0 00 10 00 10 00 10 00 10 00 10 00 10 00 10 00 10 00 10
					39 00 00 40 00 00 21 CC 03 80 03 80 03 80 03 80 03 80 03 80 03 80 03 80 03 80 03 80 03 80 03 80 03 80 03 80 03 80 03 80
					39 00 00 40 00 00 21 CD 09 40 09 40 09 40 09 40 09 40 09 40 06 C0 06 C0 06 C0 06 C0 06 C0 01 C0 01 C0 01 C0 01 C0 01 C0
					39 00 00 40 00 00 0E D0 10 80 00 3F FF 3F FF 3F FF 01 01 01 01
					39 00 00 40 00 00 19 D1 77 77 77 77 77 77 77 77 0E 0F 10 11 12 13 14 15 16 17 18 19 1A 1A 1A 1A
					39 00 00 40 00 00 21 D2 00 05 00 0F 00 1E 00 2E 00 80 01 2E 02 61 05 4C 0A 29 13 E2 1A 5E 34 BC 3F FF 3F FF 3F FF 3F FF
					39 00 00 40 00 00 21 D3 14 00 12 00 11 00 0D 00 0B 00 09 00 03 E0 00 20 00 20 00 20 00 20 00 20 00 20 00 20 00 20 00 20
					39 00 00 40 00 00 21 D4 03 80 03 80 03 80 03 80 03 80 03 80 03 80 03 80 03 80 03 80 03 80 03 80 03 80 03 80 03 80 03 80
					39 00 00 40 00 00 21 D5 09 40 09 40 09 40 09 40 09 40 09 40 06 C0 06 C0 06 C0 06 C0 06 C0 01 C0 01 C0 01 C0 01 C0 01 C0
					39 00 00 40 00 00 0E E0 10 80 00 3F FF 3F FF 3F FF 00 00 00 00
					39 00 00 40 00 00 19 E1 77 77 77 77 77 77 77 77 1E 1F 20 21 22 23 24 25 26 27 28 29 2A 2A 2A 2A
					39 00 00 40 00 00 21 E2 00 05 00 0F 00 1E 00 2E 00 80 01 2E 02 61 05 4C 0A 29 13 E2 1A 5E 34 BC 3F FF 3F FF 3F FF 3F FF
					39 00 00 40 00 00 21 E3 0D 58 0C 00 0B 54 08 AC 07 54 06 00 02 94 00 10 00 10 00 10 00 10 00 10 00 10 00 10 00 10 00 10
					39 00 00 40 00 00 21 E4 03 80 03 80 03 80 03 80 03 80 03 80 03 80 03 80 03 80 03 80 03 80 03 80 03 80 03 80 03 80 03 80
					39 00 00 40 00 00 21 E5 09 40 09 40 09 40 09 40 09 40 09 40 06 C0 06 C0 06 C0 06 C0 06 C0 01 C0 01 C0 01 C0 01 C0 01 C0
					39 00 00 40 00 00 0F DD 00 04 04 04 00 00 04 04 00 00 04 04 00 00
					39 00 00 00 00 00 0D DE 00 00 80 1B 00 00 80 1C 00 00 80 1D
					39 00 00 40 00 00 03 F0 AA 13
					39 00 00 40 00 00 1F CE 87 3E 43 33 00 BA 00 BA 00 BA 88 40 44 2D 01 37 01 37 01 37 89 64 62 49 02 6E 02 6E 02 6E
					39 00 00 40 00 00 1F D6 87 3E 43 33 00 BA 00 BA 00 BA 88 40 44 2D 01 37 01 37 01 37 89 64 62 49 02 6E 02 6E 02 6E
					39 00 00 40 00 00 1F E6 87 3E 43 33 00 BA 00 BA 00 BA 88 40 44 2D 01 37 01 37 01 37 89 64 62 49 02 6E 02 6E 02 6E
					39 00 00 40 00 00 1F EE 87 3E 43 33 00 BA 00 BA 00 BA 88 40 44 2D 01 37 01 37 01 37 89 64 62 49 02 6E 02 6E 02 6E
					39 00 00 40 00 00 03 F0 AA 14
					39 00 00 40 00 00 0B B2 3F 37 00 00 00 00 00 00 00 00
					39 00 00 40 00 00 17 B5 00 00 00 00 1B 1B 1B 1B 1B 1B 1B 1B 0B 02 00 00 00 00 00 00 00 00
					39 00 00 40 00 00 0E BC A0 00 00 0D 13 1B 63 1B 63 1B 63 1B 63
					39 00 00 40 00 00 0E BF 90 10 00 0D 22 00 28 00 28 00 28 00 28
					39 00 00 40 00 00 07 B9 00 00 0D 00 00 00
					39 00 00 40 00 00 03 F0 AA 14
					39 00 00 40 00 00 18 B0 00 00 00 70 00 00 00 10 10 10 10 10 10 10 10 10 10 10 10 10 10 10 10
					39 00 00 40 00 00 02 65 17
					39 00 00 40 00 00 0D B0 10 10 10 10 10 10 10 10 10 10 10 10
					39 00 00 40 00 00 03 F0 AA 15
					39 00 00 40 00 00 03 B0 0F 00
					39 00 00 40 00 00 0B B1 A6 25 A6 45 A6 65 A6 25 00 00
					39 00 00 40 00 00 13 B2 37 03 00 77 33 00 70 30 00 05 31 30 55 11 00 50 10 00
					39 00 00 40 00 00 13 B4 26 44 00 66 44 00 60 40 00 41 25 00 11 55 00 10 50 00
					39 00 00 40 00 00 13 B5 26 24 00 66 44 00 60 40 00 26 00 00 66 00 00 60 00 00
					39 00 00 40 00 00 13 B6 26 44 00 66 44 00 60 40 00 44 22 00 44 22 00 40 20 00
					39 00 00 40 00 00 13 B7 26 44 00 66 44 00 60 40 00 44 22 00 44 22 00 40 20 00
					39 00 00 40 00 00 09 BC 08 01 08 01 08 01 08 01
					39 00 00 40 00 00 05 BD 00 00 00 00
					39 00 00 40 00 00 0C BE 22 00 11 11 11 22 44 44 44 44 00
					39 00 00 40 00 00 02 C4 01
					39 00 00 40 00 00 11 C5 08 5A 00 00 08 5A 00 00 08 5A 00 00 08 5A 00 00
					39 00 00 40 00 00 02 65 01
					39 00 00 40 00 00 02 C4 02
					39 00 00 40 00 00 09 D2 00 01 06 C6 07 F3 0E B8
					39 00 00 40 00 00 0E E0 13 01 02 40 00 00 00 08 00 E4 E4 24 24
					39 00 00 40 00 00 02 65 10
					39 00 00 40 00 00 02 C5 01
					39 00 00 40 00 00 03 F0 AA 15
					39 00 00 00 00 00 05 BF 00 49 D9 30
					39 00 00 40 00 00 03 F0 AA 16
					39 00 00 40 00 00 05 B0 0C 37 34 37
					39 00 00 40 00 00 05 B1 00 37 35 37
					39 00 00 40 00 00 05 B2 23 37 22 37
					39 00 00 40 00 00 05 B3 35 37 0E 37
					39 00 00 40 00 00 05 B4 0F 37 10 37
					39 00 00 40 00 00 06 B5 11 37 37 37 37
					39 00 00 40 00 00 05 B6 0C 37 34 37
					39 00 00 40 00 00 05 B7 00 37 35 37
					39 00 00 40 00 00 05 B8 23 37 22 37
					39 00 00 40 00 00 05 B9 35 37 0E 37
					39 00 00 40 00 00 05 BA 0F 37 10 37
					39 00 00 40 00 00 06 BB 11 37 37 37 37
					39 00 00 40 00 00 0D D1 00 00 00 00 00 00 00 00 00 00 00 00
					39 00 00 40 00 00 02 65 0C
					39 00 00 40 00 00 04 D1 03 03 00
					39 00 00 40 00 00 03 F0 AA 16
					39 00 00 40 00 00 02 E1 70
					39 00 00 40 00 00 02 65 06
					39 00 00 40 00 00 04 E1 00 00 00
					39 00 00 40 00 00 02 65 0F
					39 00 00 40 00 00 05 E1 00 00 00 00
					39 00 00 40 00 00 02 65 20
					39 00 00 40 00 00 05 E2 E0 60 C0 E0
					39 00 00 40 00 00 02 65 08
					39 00 00 40 00 00 02 D2 10
					39 00 00 40 00 00 02 65 13
					39 00 00 40 00 00 0F D2 0A 40 0A 40 0A 40 0A 40 0A 40 0A 40 0A 40
					39 00 00 40 00 00 02 65 21
					39 00 00 40 00 00 0F D2 0A 70 0D F0 14 F0 14 F0 0A 70 0A 70 0A 70
					39 00 00 40 00 00 03 F0 AA 17
					39 00 00 40 00 00 02 B0 B0
					39 00 00 40 00 00 02 B4 08
					39 00 00 40 00 00 07 C0 21 43 65 21 43 65
					39 00 00 40 00 00 02 C2 80
					39 00 00 40 00 00 13 B2 00 40 00 00 40 00 00 20 20 00 40 00 00 40 00 00 20 20
					39 00 00 40 00 00 02 65 1A
					39 00 00 40 00 00 0D B2 20 00 00 20 00 00 20 00 00 20 00 00
					39 00 00 40 00 00 02 65 26
					39 00 00 40 00 00 0D B2 10 F0 10 10 F0 10 20 F0 F0 20 F0 F0
					39 00 00 40 00 00 02 65 03
					39 00 00 40 00 00 02 B1 12
					39 00 00 40 00 00 02 65 05
					39 00 00 40 00 00 05 B4 02 04 08 10
					39 00 00 40 00 00 02 65 11
					39 00 00 40 00 00 05 B4 03 06 0C 18
					39 00 00 40 00 00 25 B3 A0 A0 80 A0 A0 80 80 A0 A0 80 C0 80 00 40 00 00 20 20 20 20 00 20 20 00 00 20 20 00 40 00 00 40 00 00 20 20
					39 00 00 00 00 00 03 C3 88 88
					39 00 00 40 00 00 03 F0 AA 19
					39 00 00 40 00 00 06 D0 01 00 07 00 00
					39 00 00 40 00 00 0D D1 43 33 34 43 34 44 34 43 33 33 33 33
					39 00 00 40 00 00 09 D2 88 88 88 88 88 88 88 88
					39 00 00 40 00 00 03 D3 80 80
					39 00 00 40 00 00 31 D4 00 00 00 00 00 00 00 00 00 00 00 00 00 00 00 00 00 00 00 00 00 00 00 00 00 00 00 00 00 00 00 00 05 0A 0A 0A 0A 1E 1E 1E 1E 1E 1E 28 28 28 28 28
					39 00 00 40 00 00 31 D5 00 00 00 00 00 00 00 00 00 00 00 00 00 00 00 00 00 00 00 00 00 00 00 00 00 00 00 00 00 00 00 00 00 00 00 00 00 00 00 00 00 00 00 00 00 00 00 00
					39 00 00 40 00 00 31 D6 00 00 00 00 00 00 00 00 00 00 00 00 00 00 00 00 00 00 00 00 00 00 00 00 00 00 00 00 00 00 00 00 FE FB FB FB FB EC EC EC EC EC EC EC EC EC EC EC
					39 00 00 40 00 00 31 D7 00 00 00 00 00 00 00 00 00 00 00 00 00 00 00 00 00 00 00 00 00 00 00 00 00 00 00 00 00 00 00 00 00 00 00 00 00 00 00 00 00 00 00 00 00 00 00 00
					39 00 00 40 00 00 31 D8 00 00 00 00 00 00 00 00 00 00 00 00 00 00 00 00 00 00 00 00 00 00 00 00 00 00 00 00 00 00 00 00 00 00 00 00 00 F6 F6 F6 F6 F6 F6 F6 F6 F6 F6 F6
					39 00 00 40 00 00 31 D9 00 00 00 00 00 00 00 00 00 00 00 00 00 00 00 00 00 00 00 00 00 00 00 00 00 00 00 00 00 00 00 00 00 00 00 00 00 00 00 00 00 00 00 00 00 00 00 00
					39 00 00 40 00 00 31 DD 00 00 00 00 00 00 00 00 00 00 00 00 00 00 00 00 00 00 00 00 00 00 00 00 00 00 00 00 00 00 00 00 00 00 00 00 00 00 00 00 00 00 00 00 00 00 00 00
					39 00 00 40 00 00 31 DE 00 00 00 00 00 00 00 00 00 00 00 00 00 00 00 00 00 00 00 00 00 00 00 00 00 00 00 00 00 00 00 00 00 00 00 00 00 00 00 00 00 00 00 00 00 00 00 00
					39 00 00 00 00 00 19 DF 00 00 00 00 00 00 00 00 00 00 00 00 00 00 00 00 00 00 00 00 00 00 00 00
					39 00 00 40 00 00 03 F0 AA 19
					39 00 00 40 00 00 02 65 01
					39 00 00 40 00 00 09 C0 86 0C 01 3F FF 00 80 08
					39 00 00 40 00 00 05 C1 55 55 55 55
					39 00 00 40 00 00 13 C2 00 0F 00 0F 00 0F 02 61 02 61 02 61 1A 5E 1A 5E 1A 5E
					39 00 00 40 00 00 25 C3 00 05 00 0F 00 1E 00 2E 00 80 01 2E 02 61 05 4C 0A 29 13 E2 1A 5E 34 BC 00 19 00 2B 00 3E 00 61 00 8F 00 CE
					39 00 00 40 00 00 02 C5 00
					39 00 00 40 00 00 03 F0 AA 19
					39 00 00 40 00 00 04 C9 00 00 00
					39 00 00 40 00 00 02 65 03
					39 00 00 40 00 00 04 C9 03 D1 40
					39 00 00 40 00 00 03 F0 AA 1A
					39 00 00 40 00 00 02 65 01
					39 00 00 40 00 00 03 B0 00 00
					39 00 00 40 00 00 0F B1 0C 70 00 84 84 84 04 07 00 00 00 00 00 00
					39 00 00 40 00 00 03 F0 AA 1A
					39 00 00 40 00 00 0F B9 00 00 00 00 00 00 00 00 00 00 00 00 00 00
					39 00 00 40 00 00 11 B8 01 02 03 04 05 06 07 00 00 00 00 00 00 00 00 00
					39 00 00 40 00 00 21 BA 00 05 00 0F 00 1E 00 2E 00 80 01 2E 02 61 05 4C 0A 29 13 E2 1A 5E 34 BC 3F FF 3F FF 3F FF 3F FF
					39 00 00 40 00 00 21 BB 00 05 00 0F 00 1E 00 2E 00 80 01 2E 02 61 05 4C 0A 29 13 E2 1A 5E 34 BC 3F FF 3F FF 3F FF 3F FF
					39 00 00 00 00 00 07 B2 42 53 66 76 87 77
					39 00 00 40 00 00 03 F0 AA 1E
					39 00 00 40 00 00 04 C8 0A 45 10
					39 00 00 40 00 00 02 65 20
					39 00 00 40 00 00 21 CA 00 44 00 44 00 44 00 44 00 44 00 44 00 44 00 44 00 44 00 44 00 76 01 E8 01 E8 01 E8 01 E8 01 E8
					39 00 00 40 00 00 02 65 40
					39 00 00 40 00 00 21 CA 00 30 00 30 00 30 00 30 00 30 00 30 00 30 00 30 00 30 00 30 00 62 01 D4 01 D4 01 D4 01 D4 01 D4
					39 00 00 40 00 00 02 65 20
					39 00 00 40 00 00 21 CE 00 58 00 58 00 58 00 58 00 58 00 58 00 58 00 58 00 58 00 58 00 8A 01 FC 01 FC 01 FC 01 FC 01 FC
					39 00 00 40 00 00 02 65 40
					39 00 00 40 00 00 21 CE 00 44 00 44 00 44 00 44 00 44 00 44 00 44 00 44 00 44 00 44 00 76 01 E8 01 E8 01 E8 01 E8 01 E8
					39 00 00 40 00 00 02 65 20
					39 00 00 40 00 00 21 D2 00 44 00 44 00 44 00 44 00 44 00 44 00 44 00 44 00 44 00 44 00 76 01 E8 01 E8 01 E8 01 E8 01 E8
					39 00 00 40 00 00 02 65 40
					39 00 00 40 00 00 21 D2 00 30 00 30 00 30 00 30 00 30 00 30 00 30 00 30 00 30 00 30 00 62 01 D4 01 D4 01 D4 01 D4 01 D4
					39 00 00 40 00 00 21 C9 00 05 00 0F 00 1E 00 2E 00 80 01 2E 02 61 05 4C 0A 29 13 E2 1A 5E 34 BC 3F FF 3F FF 3F FF 3F FF
					39 00 00 40 00 00 21 CD 00 05 00 0F 00 1E 00 2E 00 80 01 2E 02 61 05 4C 0A 29 13 E2 1A 5E 34 BC 3F FF 3F FF 3F FF 3F FF
					39 00 00 40 00 00 21 D1 00 05 00 0F 00 1E 00 2E 00 80 01 2E 02 61 05 4C 0A 29 13 E2 1A 5E 34 BC 3F FF 3F FF 3F FF 3F FF
					39 00 00 00 00 00 21 D5 00 05 00 0F 00 1E 00 2E 00 80 01 2E 02 61 05 4C 0A 29 13 E2 1A 5E 34 BC 3F FF 3F FF 3F FF 3F FF
					39 00 00 40 00 00 03 F0 AA 10
					39 00 00 40 00 00 02 65 04
					39 00 00 40 00 00 04 EA 48 CB 01
					39 00 00 40 00 00 02 65 0D
					39 00 00 40 00 00 04 EA 0C 00 01
					39 00 00 40 00 00 02 65 10
					39 00 00 40 00 00 04 EA 0C 80 01
					39 00 00 40 00 00 02 65 13
					39 00 00 40 00 00 04 EA C8 AE 01
					39 00 00 40 00 00 02 65 16
					39 00 00 40 00 00 04 EA 64 C1 01
					39 00 00 40 00 00 02 65 19
					39 00 00 40 00 00 04 EA 98 A5 01
					39 00 00 40 00 00 02 65 28
					39 00 00 40 00 00 04 EA 0C 00 00
					39 00 00 40 00 00 02 65 0A
					39 00 00 40 00 00 02 EB 10
					39 00 00 40 00 00 03 F0 AA 10
					39 00 00 40 00 00 02 65 01
					39 00 00 40 00 00 02 CF 87
					39 00 00 40 00 00 02 59 09
					39 00 00 40 00 00 03 F0 AA 10
					39 00 00 40 00 00 04 EB 00 00 30
					39 00 00 40 00 00 05 EA 0F 41 00 08
					39 00 00 40 00 00 03 F0 AA 11
					39 00 00 40 00 00 02 C3 00
					39 00 00 40 00 00 03 F0 AA 18
					39 00 00 40 00 00 02 B0 80
					39 00 00 40 00 00 03 F0 AA 19
					39 00 00 40 00 00 02 D0 01
					39 00 00 40 00 00 03 F0 AA 19
					39 00 00 40 00 00 02 C0 E0
					39 00 00 40 00 00 03 F0 AA 1A
					39 00 00 40 00 00 02 B0 01
					39 00 00 40 00 00 03 FF 5A 83
					39 00 00 40 00 00 02 65 0B
					39 00 00 40 00 00 02 F8 05
					39 00 00 40 00 00 03 FF 5A 81
					39 00 00 40 00 00 02 65 03
					39 00 00 40 00 00 02 F3 04
					39 00 00 40 00 00 02 65 05
					39 00 00 40 00 00 02 F3 48
					39 00 00 40 00 00 03 FF 5A 80
					39 00 00 40 00 00 02 65 0E
					39 00 00 40 00 00 02 F9 A1
					39 00 00 40 00 00 02 03 01
					39 00 00 40 00 00 02 35 00
					39 00 00 40 00 00 02 53 20
					39 00 00 40 00 00 03 51 00 00
					39 00 00 40 00 00 02 6B 00
					39 00 00 40 00 00 02 6F 02
					39 00 00 40 00 00 02 6C 02
					39 00 00 40 00 00 02 6D 00
					39 00 00 40 00 00 5F 70 12 00 00 AB 30 80 09 CE 04 84 00 0A 02 42 02 42 02 00 01 19 00 20 01 A0 00 08 00 01 00 E4 09 8D 18 00 11 00 07 10 20 00 06 0F 0F 33 0E 1C 2A 38 46 54 62 69 70 77 79 7B 7D 7E 02 02 22 00 2A 40 2A BE 3A FC 3A FA 3A F8 3B 38 3B 78 3B B6 4B B6 4B F4 4B F4 6C 34 84 74 00 00 00 00 00 00
					39 00 00 40 00 00 02 72 00
					39 00 00 40 00 00 03 F0 AA 00
					39 00 00 40 00 00 03 FF 5A 00
					39 00 00 40 00 00 03 FF 5A 80
					39 00 00 40 00 00 02 65 0E
					39 00 00 40 00 00 02 F9 A1
					39 00 00 00 78 00 01 11
					39 00 00 00 00 00 01 29
					//GIR & Slice ACL ON
					39 00 00 40 00 00 02 A4 01
					39 00 00 40 00 00 03 F0 AA 11
					39 00 00 40 00 00 02 D5 13
					39 00 00 40 00 00 02 C3 31
					39 00 00 40 00 00 02 A4 00
					39 00 00 00 00 00 02 A6 01
					//end
					//OSC sync to mipi clk begin
					39 00 00 40 00 00 03 F0 AA 14
					39 00 00 40 00 00 02 C1 0B
					39 00 00 40 00 00 20 C3 01 21 20 03 AD 03 AD 03 AD 03 AD 03 AD 03 AD 03 AD 00 C7 00 C7 00 C7 00 C7 00 31 00 31 00 31
					//end
					39 00 00 40 00 00 03 F0 AA 1E
					39 00 00 40 00 00 02 65 02
					39 00 00 00 00 00 02 C8 10
					39 00 00 40 00 00 03 F0 AA 10
					39 00 00 40 00 00 02 65 04
					39 00 00 40 00 00 02 B0 02
					//AOD timing optimization
					39 00 00 40 00 00 03 F0 AA 12
					39 00 00 40 00 00 02 65 02
					39 00 00 40 00 00 02 D1 00
					//MIPI Error Gating Set For ESD
					//check MIPI HS timeout
					39 00 00 40 00 00 03 F0 AA 10
					39 00 00 40 00 00 02 65 0B
					39 00 00 40 00 00 03 CF DD 79
					39 00 00 40 00 00 03 FF 5A 00
					39 00 00 00 00 00 03 F0 AA 00
					//AOD ISOP/IGOP/Pump clk
					39 00 00 40 00 00 03 F0 AA 10
					39 00 00 40 00 00 02 65 0A
					39 00 00 40 00 00 07 C4 00 00 00 00 00 00
					39 00 00 40 00 00 02 65 11
					39 00 00 40 00 00 02 C4 00
					39 00 00 40 00 00 03 F0 AA 12
					39 00 00 40 00 00 0C B2 75 35 77 75 35 77 75 35 77 57 05
					39 00 00 00 00 00 03 F0 AA 00
					//MIPI ULPS error ESD off
					39 00 00 40 00 00 03 F0 AA 10
					39 00 00 40 00 00 02 65 09
					39 00 00 40 00 00 02 CF 5B
					39 00 00 00 00 00 03 F0 AA 00
		        ];
				qcom,mdss-dsi-on-command-state = "dsi_lp_mode";
                 qcom,mdss-dsi-timing-switch-command = [
					//90hz
					39 00 00 00 00 00 02 6C 02
				];
				qcom,mdss-dsi-timing-switch-command-state = "dsi_hs_mode";
				mi,mdss-dsi-csc-by-temper-comp-off-mode-command = [
					39 00 00 40 00 00 03 F0 AA 1A
					39 00 00 40 00 00 02 B0 01
					39 00 00 00 00 00 02 6B 00
					39 00 00 00 00 00 03 F0 AA 00
				];
				mi,mdss-dsi-csc-by-temper-comp-off-mode-command-state = "dsi_hs_mode";
				mi,mdss-dsi-csc-by-temper-comp-32-36-mode-command = [
					39 00 00 40 00 00 03 F0 AA 1A
					39 00 00 40 00 00 02 B0 01
					39 00 00 00 00 00 02 6B 01
					39 00 00 00 00 00 03 F0 AA 00
				];
				mi,mdss-dsi-csc-by-temper-comp-32-36-mode-command-state = "dsi_hs_mode";
				mi,mdss-dsi-csc-by-temper-comp-36-40-mode-command = [
					39 00 00 40 00 00 03 F0 AA 1A
					39 00 00 40 00 00 02 B0 01
					39 00 00 00 00 00 02 6B 02
					39 00 00 00 00 00 03 F0 AA 00
				];
				mi,mdss-dsi-csc-by-temper-comp-36-40-mode-command-state = "dsi_hs_mode";
				mi,mdss-dsi-csc-by-temper-comp-40-mode-command = [
					39 00 00 40 00 00 03 F0 AA 1A
					39 00 00 40 00 00 02 B0 01
					39 00 00 00 00 00 02 6B 04
					39 00 00 00 00 00 03 F0 AA 00
				];
				mi,mdss-dsi-csc-by-temper-comp-40-mode-command-state = "dsi_hs_mode";
				mi,mdss-dsi-csc-by-temper-comp-45-mode-command = [
					39 00 00 40 00 00 03 F0 AA 1A
					39 00 00 40 00 00 02 B0 01
					39 00 00 00 00 00 02 6B 06
					39 00 00 00 00 00 03 F0 AA 00
				];
				mi,mdss-dsi-csc-by-temper-comp-45-mode-command-state = "dsi_hs_mode";
			};
			timing@2 {
				#include "dsi-panel-p11-42-0d-0a-p10-dsc-cmd-common.dtsi"
				cell-index = <2>;
				qcom,mdss-dsi-panel-framerate = <60>;
				qcom,mdss-dsi-h-sync-skew = <0>;
				qcom,mdss-dsi-on-command = [
					39 00 00 40 00 00 03 F0 AA 10
					39 00 00 40 00 00 0A B0 04 E7 01 21 12 04 84 04 E7
					39 00 00 40 00 00 16 B1 01 9F 00 11 00 21 00 01 9F 00 11 0A 21 00 01 9F 00 11 03 79 00
					39 00 00 40 00 00 16 B2 01 9F 00 11 00 21 03 01 9F 00 11 00 21 03 01 9F 00 11 00 21 03
					39 00 00 40 00 00 11 C1 04 00 00 00 04 00 00 00 04 00 00 00 04 00 00 00
					39 00 00 40 00 00 04 C3 53 44 00
					39 00 00 40 00 00 02 65 13
					39 00 00 40 00 00 02 C4 80
					39 00 00 40 00 00 09 C4 28 28 28 28 28 28 28 28
					39 00 00 40 00 00 02 65 0A
					39 00 00 40 00 00 07 C4 28 28 28 28 28 28
					39 00 00 40 00 00 06 C6 62 52 00 00 A0
					39 00 00 40 00 00 02 CF 09
					39 00 00 40 00 00 02 65 02
					39 00 00 40 00 00 02 CF 1C
					39 00 00 40 00 00 02 65 04
					39 00 00 40 00 00 03 CF 93 92
					39 00 00 40 00 00 02 65 09
					39 00 00 40 00 00 02 CF 5F
					39 00 00 40 00 00 02 65 0B
					39 00 00 40 00 00 03 CF FD 79
					39 00 00 40 00 00 02 B6 00
					39 00 00 40 00 00 02 BD 60
					39 00 00 40 00 00 14 D0 84 68 22 22 00 0F 12 12 66 66 20 00 05 14 14 55 55 50 00
					39 00 00 40 00 00 2A D1 00 35 0F 0F 0F 0F 47 00 00 4F 00 00 00 00 33 47 4F 00 00 00 00 29 11 11 11 11 2B 00 00 32 00 00 00 00 29 2A 33 00 00 00 00
					39 00 00 40 00 00 31 D3 00 05 00 0F 00 1E 00 2E 00 80 01 2E 02 61 05 4C 0A 29 13 E2 1A 5E 34 BC 3F FF 3F FF 3F FF 3F FF 1F 1F 1F 1F 1F 1F 1F 24 21 1F 1A 00 00 00 00 00
					39 00 00 40 00 00 31 D4 00 05 00 0F 00 1E 00 2E 00 80 01 2E 02 61 05 4C 0A 29 13 E2 1A 5E 34 BC 3F FF 3F FF 3F FF 3F FF 1F 1F 1F 1F 1F 1F 1F 24 21 1F 1A 00 00 00 00 00
					39 00 00 40 00 00 31 D5 00 05 00 0F 00 1E 00 2E 00 80 01 2E 02 61 05 4C 0A 29 13 E2 1A 5E 34 BC 3F FF 3F FF 3F FF 3F FF 1F 1F 1F 1F 1F 1F 1F 24 21 1F 1A 00 00 00 00 00
					39 00 00 40 00 00 31 D6 00 05 00 0F 00 1E 00 2E 00 80 01 2E 02 61 05 4C 0A 29 13 E2 1A 5E 34 BC 3F FF 3F FF 3F FF 3F FF 1F 1F 1F 1F 1F 1F 1F 24 21 1F 1A 00 00 00 00 00
					39 00 00 40 00 00 03 E7 40 46
					39 00 00 40 00 00 02 65 0D
					39 00 00 00 00 00 02 C8 01
					39 00 00 40 00 00 03 F0 AA 11
					39 00 00 40 00 00 1C D0 A1 2A 90 90 90 2A 90 90 90 01 3F 00 00 00 3F 10 10 10 3F 80 80 80 00 70 5F 20 81
					39 00 00 40 00 00 02 65 2A
					39 00 00 40 00 00 03 D0 17 60
					39 00 00 40 00 00 02 65 03
					39 00 00 40 00 00 04 C0 14 1E 20
					39 00 00 40 00 00 03 F0 AA 11
					39 00 00 40 00 00 02 65 01
					39 00 00 40 00 00 07 C3 34 BC 3F FF 01 6C
					39 00 00 40 00 00 02 65 07
					39 00 00 40 00 00 05 C3 56 45 32 65
					39 00 00 40 00 00 02 65 0B
					39 00 00 40 00 00 0D C3 FF BF 02 FF FF FF BC 92 8B 71 F7 04
					39 00 00 40 00 00 02 65 17
					39 00 00 40 00 00 05 C3 55 55 55 55
					39 00 00 40 00 00 02 65 1B
					39 00 00 40 00 00 0C C3 00 01 00 1C 38 57 76 9C C6 E1 00
					39 00 00 40 00 00 03 F0 AA 12
					39 00 00 40 00 00 05 B1 5F 5F 5F 13
					39 00 00 40 00 00 0C B2 44 55 44 44 55 44 44 55 44 44 05
					39 00 00 40 00 00 0F B3 06 10 06 10 06 10 06 10 06 10 06 10 06 10
					39 00 00 40 00 00 0F B5 03 80 03 00 03 80 03 00 03 80 03 00 03 80
					39 00 00 40 00 00 0F B6 06 C0 0E 40 06 C0 0E 40 06 C0 0E 40 06 C0
					39 00 00 40 00 00 0F B7 68 68 68 68 68 68 68 68 68 68 68 68 68 68
					39 00 00 40 00 00 1D B8 02 04 02 04 02 04 02 04 02 04 02 04 02 04 02 04 02 04 02 04 02 04 02 04 02 04 02 04
					39 00 00 40 00 00 09 B9 01 B6 01 B6 01 B6 01 B6
					39 00 00 40 00 00 02 65 08
					39 00 00 40 00 00 07 B9 01 52 01 52 01 52
					39 00 00 40 00 00 02 65 16
					39 00 00 40 00 00 07 B9 00 58 00 58 00 58
					39 00 00 40 00 00 02 65 24
					39 00 00 40 00 00 07 B9 00 44 00 44 00 44
					39 00 00 40 00 00 02 65 54
					39 00 00 40 00 00 03 B9 00 44
					39 00 00 40 00 00 04 BB 00 32 00
					39 00 00 40 00 00 02 65 05
					39 00 00 40 00 00 04 BB B3 B3 B3
					39 00 00 40 00 00 07 C7 FF 78 43 5A 33 33
					39 00 00 40 00 00 0D E9 00 00 00 00 00 00 00 00 00 00 00 00
					39 00 00 40 00 00 02 CF 03
					39 00 00 40 00 00 04 D1 04 00 11
					39 00 00 40 00 00 0B D2 0F 00 00 1A 00 1A 00 1A 00 1A
					39 00 00 40 00 00 03 D6 02 00
					39 00 00 40 00 00 02 C9 3C
					39 00 00 00 00 00 2B C4 00 00 02 00 00 0F 00 00 02 00 00 0F 00 00 02 00 00 0F 00 00 02 00 00 0F 00 00 02 00 00 0F 00 00 02 00 00 0F 00 00 02 00 00 0F
					39 00 00 40 00 00 03 F0 AA 13
					39 00 00 40 00 00 11 BD 20 11 0A 04 04 0A 11 20 2A 15 15 2A 2A 2A 15 15
					39 00 00 40 00 00 0A C2 01 34 BC 34 BC 34 BC 34 BC
					39 00 00 40 00 00 07 C3 21 43 65 21 43 65
					39 00 00 40 00 00 02 65 01
					39 00 00 40 00 00 02 EF E0
					39 00 00 40 00 00 02 65 03
					39 00 00 40 00 00 02 EF E0
					39 00 00 40 00 00 0E C8 10 C0 15 3F FF 3F FF 3F FF 00 00 00 00
					39 00 00 40 00 00 19 C9 77 77 77 77 77 77 77 77 01 02 03 04 05 06 07 08 09 0A 0B 0C 0D 0D 0D 0D
					39 00 00 40 00 00 21 CA 00 05 00 0F 00 1E 00 2E 00 80 01 2E 02 61 05 4C 0A 29 13 E2 1A 5E 34 BC 3F FF 3F FF 3F FF 3F FF
					39 00 00 40 00 00 21 CB 0A 00 09 00 08 80 06 80 05 80 04 80 01 F0 00 10 00 10 00 10 00 10 00 10 00 10 00 10 00 10 00 10
					39 00 00 40 00 00 21 CC 03 80 03 80 03 80 03 80 03 80 03 80 03 80 03 80 03 80 03 80 03 80 03 80 03 80 03 80 03 80 03 80
					39 00 00 40 00 00 21 CD 09 40 09 40 09 40 09 40 09 40 09 40 06 C0 06 C0 06 C0 06 C0 06 C0 01 C0 01 C0 01 C0 01 C0 01 C0
					39 00 00 40 00 00 0E D0 10 80 00 3F FF 3F FF 3F FF 01 01 01 01
					39 00 00 40 00 00 19 D1 77 77 77 77 77 77 77 77 0E 0F 10 11 12 13 14 15 16 17 18 19 1A 1A 1A 1A
					39 00 00 40 00 00 21 D2 00 05 00 0F 00 1E 00 2E 00 80 01 2E 02 61 05 4C 0A 29 13 E2 1A 5E 34 BC 3F FF 3F FF 3F FF 3F FF
					39 00 00 40 00 00 21 D3 14 00 12 00 11 00 0D 00 0B 00 09 00 03 E0 00 20 00 20 00 20 00 20 00 20 00 20 00 20 00 20 00 20
					39 00 00 40 00 00 21 D4 03 80 03 80 03 80 03 80 03 80 03 80 03 80 03 80 03 80 03 80 03 80 03 80 03 80 03 80 03 80 03 80
					39 00 00 40 00 00 21 D5 09 40 09 40 09 40 09 40 09 40 09 40 06 C0 06 C0 06 C0 06 C0 06 C0 01 C0 01 C0 01 C0 01 C0 01 C0
					39 00 00 40 00 00 0E E0 10 80 00 3F FF 3F FF 3F FF 00 00 00 00
					39 00 00 40 00 00 19 E1 77 77 77 77 77 77 77 77 1E 1F 20 21 22 23 24 25 26 27 28 29 2A 2A 2A 2A
					39 00 00 40 00 00 21 E2 00 05 00 0F 00 1E 00 2E 00 80 01 2E 02 61 05 4C 0A 29 13 E2 1A 5E 34 BC 3F FF 3F FF 3F FF 3F FF
					39 00 00 40 00 00 21 E3 0D 58 0C 00 0B 54 08 AC 07 54 06 00 02 94 00 10 00 10 00 10 00 10 00 10 00 10 00 10 00 10 00 10
					39 00 00 40 00 00 21 E4 03 80 03 80 03 80 03 80 03 80 03 80 03 80 03 80 03 80 03 80 03 80 03 80 03 80 03 80 03 80 03 80
					39 00 00 40 00 00 21 E5 09 40 09 40 09 40 09 40 09 40 09 40 06 C0 06 C0 06 C0 06 C0 06 C0 01 C0 01 C0 01 C0 01 C0 01 C0
					39 00 00 40 00 00 0F DD 00 04 04 04 00 00 04 04 00 00 04 04 00 00
					39 00 00 00 00 00 0D DE 00 00 80 1B 00 00 80 1C 00 00 80 1D
					39 00 00 40 00 00 03 F0 AA 13
					39 00 00 40 00 00 1F CE 87 3E 43 33 00 BA 00 BA 00 BA 88 40 44 2D 01 37 01 37 01 37 89 64 62 49 02 6E 02 6E 02 6E
					39 00 00 40 00 00 1F D6 87 3E 43 33 00 BA 00 BA 00 BA 88 40 44 2D 01 37 01 37 01 37 89 64 62 49 02 6E 02 6E 02 6E
					39 00 00 40 00 00 1F E6 87 3E 43 33 00 BA 00 BA 00 BA 88 40 44 2D 01 37 01 37 01 37 89 64 62 49 02 6E 02 6E 02 6E
					39 00 00 40 00 00 1F EE 87 3E 43 33 00 BA 00 BA 00 BA 88 40 44 2D 01 37 01 37 01 37 89 64 62 49 02 6E 02 6E 02 6E
					39 00 00 40 00 00 03 F0 AA 14
					39 00 00 40 00 00 0B B2 3F 37 00 00 00 00 00 00 00 00
					39 00 00 40 00 00 17 B5 00 00 00 00 1B 1B 1B 1B 1B 1B 1B 1B 0B 02 00 00 00 00 00 00 00 00
					39 00 00 40 00 00 0E BC A0 00 00 0D 13 1B 63 1B 63 1B 63 1B 63
					39 00 00 40 00 00 0E BF 90 10 00 0D 22 00 28 00 28 00 28 00 28
					39 00 00 40 00 00 07 B9 00 00 0D 00 00 00
					39 00 00 40 00 00 03 F0 AA 14
					39 00 00 40 00 00 18 B0 00 00 00 70 00 00 00 10 10 10 10 10 10 10 10 10 10 10 10 10 10 10 10
					39 00 00 40 00 00 02 65 17
					39 00 00 40 00 00 0D B0 10 10 10 10 10 10 10 10 10 10 10 10
					39 00 00 40 00 00 03 F0 AA 15
					39 00 00 40 00 00 03 B0 0F 00
					39 00 00 40 00 00 0B B1 A6 25 A6 45 A6 65 A6 25 00 00
					39 00 00 40 00 00 13 B2 37 03 00 77 33 00 70 30 00 05 31 30 55 11 00 50 10 00
					39 00 00 40 00 00 13 B4 26 44 00 66 44 00 60 40 00 41 25 00 11 55 00 10 50 00
					39 00 00 40 00 00 13 B5 26 24 00 66 44 00 60 40 00 26 00 00 66 00 00 60 00 00
					39 00 00 40 00 00 13 B6 26 44 00 66 44 00 60 40 00 44 22 00 44 22 00 40 20 00
					39 00 00 40 00 00 13 B7 26 44 00 66 44 00 60 40 00 44 22 00 44 22 00 40 20 00
					39 00 00 40 00 00 09 BC 08 01 08 01 08 01 08 01
					39 00 00 40 00 00 05 BD 00 00 00 00
					39 00 00 40 00 00 0C BE 22 00 11 11 11 22 44 44 44 44 00
					39 00 00 40 00 00 02 C4 01
					39 00 00 40 00 00 11 C5 08 5A 00 00 08 5A 00 00 08 5A 00 00 08 5A 00 00
					39 00 00 40 00 00 02 65 01
					39 00 00 40 00 00 02 C4 02
					39 00 00 40 00 00 09 D2 00 01 06 C6 07 F3 0E B8
					39 00 00 40 00 00 0E E0 13 01 02 40 00 00 00 08 00 E4 E4 24 24
					39 00 00 40 00 00 02 65 10
					39 00 00 40 00 00 02 C5 01
					39 00 00 40 00 00 03 F0 AA 15
					39 00 00 00 00 00 05 BF 00 49 D9 30
					39 00 00 40 00 00 03 F0 AA 16
					39 00 00 40 00 00 05 B0 0C 37 34 37
					39 00 00 40 00 00 05 B1 00 37 35 37
					39 00 00 40 00 00 05 B2 23 37 22 37
					39 00 00 40 00 00 05 B3 35 37 0E 37
					39 00 00 40 00 00 05 B4 0F 37 10 37
					39 00 00 40 00 00 06 B5 11 37 37 37 37
					39 00 00 40 00 00 05 B6 0C 37 34 37
					39 00 00 40 00 00 05 B7 00 37 35 37
					39 00 00 40 00 00 05 B8 23 37 22 37
					39 00 00 40 00 00 05 B9 35 37 0E 37
					39 00 00 40 00 00 05 BA 0F 37 10 37
					39 00 00 40 00 00 06 BB 11 37 37 37 37
					39 00 00 40 00 00 0D D1 00 00 00 00 00 00 00 00 00 00 00 00
					39 00 00 40 00 00 02 65 0C
					39 00 00 40 00 00 04 D1 03 03 00
					39 00 00 40 00 00 03 F0 AA 16
					39 00 00 40 00 00 02 E1 70
					39 00 00 40 00 00 02 65 06
					39 00 00 40 00 00 04 E1 00 00 00
					39 00 00 40 00 00 02 65 0F
					39 00 00 40 00 00 05 E1 00 00 00 00
					39 00 00 40 00 00 02 65 20
					39 00 00 40 00 00 05 E2 E0 60 C0 E0
					39 00 00 40 00 00 02 65 08
					39 00 00 40 00 00 02 D2 10
					39 00 00 40 00 00 02 65 13
					39 00 00 40 00 00 0F D2 0A 40 0A 40 0A 40 0A 40 0A 40 0A 40 0A 40
					39 00 00 40 00 00 02 65 21
					39 00 00 40 00 00 0F D2 0A 70 0D F0 14 F0 14 F0 0A 70 0A 70 0A 70
					39 00 00 40 00 00 03 F0 AA 17
					39 00 00 40 00 00 02 B0 B0
					39 00 00 40 00 00 02 B4 08
					39 00 00 40 00 00 07 C0 21 43 65 21 43 65
					39 00 00 40 00 00 02 C2 80
					39 00 00 40 00 00 13 B2 00 40 00 00 40 00 00 20 20 00 40 00 00 40 00 00 20 20
					39 00 00 40 00 00 02 65 1A
					39 00 00 40 00 00 0D B2 20 00 00 20 00 00 20 00 00 20 00 00
					39 00 00 40 00 00 02 65 26
					39 00 00 40 00 00 0D B2 10 F0 10 10 F0 10 20 F0 F0 20 F0 F0
					39 00 00 40 00 00 02 65 03
					39 00 00 40 00 00 02 B1 12
					39 00 00 40 00 00 02 65 05
					39 00 00 40 00 00 05 B4 02 04 08 10
					39 00 00 40 00 00 02 65 11
					39 00 00 40 00 00 05 B4 03 06 0C 18
					39 00 00 40 00 00 25 B3 A0 A0 80 A0 A0 80 80 A0 A0 80 C0 80 00 40 00 00 20 20 20 20 00 20 20 00 00 20 20 00 40 00 00 40 00 00 20 20
					39 00 00 00 00 00 03 C3 88 88
					39 00 00 40 00 00 03 F0 AA 19
					39 00 00 40 00 00 06 D0 01 00 07 00 00
					39 00 00 40 00 00 0D D1 43 33 34 43 34 44 34 43 33 33 33 33
					39 00 00 40 00 00 09 D2 88 88 88 88 88 88 88 88
					39 00 00 40 00 00 03 D3 80 80
					39 00 00 40 00 00 31 D4 00 00 00 00 00 00 00 00 00 00 00 00 00 00 00 00 00 00 00 00 00 00 00 00 00 00 00 00 00 00 00 00 05 0A 0A 0A 0A 1E 1E 1E 1E 1E 1E 28 28 28 28 28
					39 00 00 40 00 00 31 D5 00 00 00 00 00 00 00 00 00 00 00 00 00 00 00 00 00 00 00 00 00 00 00 00 00 00 00 00 00 00 00 00 00 00 00 00 00 00 00 00 00 00 00 00 00 00 00 00
					39 00 00 40 00 00 31 D6 00 00 00 00 00 00 00 00 00 00 00 00 00 00 00 00 00 00 00 00 00 00 00 00 00 00 00 00 00 00 00 00 FE FB FB FB FB EC EC EC EC EC EC EC EC EC EC EC
					39 00 00 40 00 00 31 D7 00 00 00 00 00 00 00 00 00 00 00 00 00 00 00 00 00 00 00 00 00 00 00 00 00 00 00 00 00 00 00 00 00 00 00 00 00 00 00 00 00 00 00 00 00 00 00 00
					39 00 00 40 00 00 31 D8 00 00 00 00 00 00 00 00 00 00 00 00 00 00 00 00 00 00 00 00 00 00 00 00 00 00 00 00 00 00 00 00 00 00 00 00 00 F6 F6 F6 F6 F6 F6 F6 F6 F6 F6 F6
					39 00 00 40 00 00 31 D9 00 00 00 00 00 00 00 00 00 00 00 00 00 00 00 00 00 00 00 00 00 00 00 00 00 00 00 00 00 00 00 00 00 00 00 00 00 00 00 00 00 00 00 00 00 00 00 00
					39 00 00 40 00 00 31 DD 00 00 00 00 00 00 00 00 00 00 00 00 00 00 00 00 00 00 00 00 00 00 00 00 00 00 00 00 00 00 00 00 00 00 00 00 00 00 00 00 00 00 00 00 00 00 00 00
					39 00 00 40 00 00 31 DE 00 00 00 00 00 00 00 00 00 00 00 00 00 00 00 00 00 00 00 00 00 00 00 00 00 00 00 00 00 00 00 00 00 00 00 00 00 00 00 00 00 00 00 00 00 00 00 00
					39 00 00 00 00 00 19 DF 00 00 00 00 00 00 00 00 00 00 00 00 00 00 00 00 00 00 00 00 00 00 00 00
					39 00 00 40 00 00 03 F0 AA 19
					39 00 00 40 00 00 02 65 01
					39 00 00 40 00 00 09 C0 86 0C 01 3F FF 00 80 08
					39 00 00 40 00 00 05 C1 55 55 55 55
					39 00 00 40 00 00 13 C2 00 0F 00 0F 00 0F 02 61 02 61 02 61 1A 5E 1A 5E 1A 5E
					39 00 00 40 00 00 25 C3 00 05 00 0F 00 1E 00 2E 00 80 01 2E 02 61 05 4C 0A 29 13 E2 1A 5E 34 BC 00 19 00 2B 00 3E 00 61 00 8F 00 CE
					39 00 00 40 00 00 02 C5 00
					39 00 00 40 00 00 03 F0 AA 19
					39 00 00 40 00 00 04 C9 00 00 00
					39 00 00 40 00 00 02 65 03
					39 00 00 40 00 00 04 C9 03 D1 40
					39 00 00 40 00 00 03 F0 AA 1A
					39 00 00 40 00 00 02 65 01
					39 00 00 40 00 00 03 B0 00 00
					39 00 00 40 00 00 0F B1 0C 70 00 84 84 84 04 07 00 00 00 00 00 00
					39 00 00 40 00 00 03 F0 AA 1A
					39 00 00 40 00 00 0F B9 00 00 00 00 00 00 00 00 00 00 00 00 00 00
					39 00 00 40 00 00 11 B8 01 02 03 04 05 06 07 00 00 00 00 00 00 00 00 00
					39 00 00 40 00 00 21 BA 00 05 00 0F 00 1E 00 2E 00 80 01 2E 02 61 05 4C 0A 29 13 E2 1A 5E 34 BC 3F FF 3F FF 3F FF 3F FF
					39 00 00 40 00 00 21 BB 00 05 00 0F 00 1E 00 2E 00 80 01 2E 02 61 05 4C 0A 29 13 E2 1A 5E 34 BC 3F FF 3F FF 3F FF 3F FF
					39 00 00 00 00 00 07 B2 42 53 66 76 87 77
					39 00 00 40 00 00 03 F0 AA 1E
					39 00 00 40 00 00 04 C8 0A 45 10
					39 00 00 40 00 00 02 65 20
					39 00 00 40 00 00 21 CA 00 44 00 44 00 44 00 44 00 44 00 44 00 44 00 44 00 44 00 44 00 76 01 E8 01 E8 01 E8 01 E8 01 E8
					39 00 00 40 00 00 02 65 40
					39 00 00 40 00 00 21 CA 00 30 00 30 00 30 00 30 00 30 00 30 00 30 00 30 00 30 00 30 00 62 01 D4 01 D4 01 D4 01 D4 01 D4
					39 00 00 40 00 00 02 65 20
					39 00 00 40 00 00 21 CE 00 58 00 58 00 58 00 58 00 58 00 58 00 58 00 58 00 58 00 58 00 8A 01 FC 01 FC 01 FC 01 FC 01 FC
					39 00 00 40 00 00 02 65 40
					39 00 00 40 00 00 21 CE 00 44 00 44 00 44 00 44 00 44 00 44 00 44 00 44 00 44 00 44 00 76 01 E8 01 E8 01 E8 01 E8 01 E8
					39 00 00 40 00 00 02 65 20
					39 00 00 40 00 00 21 D2 00 44 00 44 00 44 00 44 00 44 00 44 00 44 00 44 00 44 00 44 00 76 01 E8 01 E8 01 E8 01 E8 01 E8
					39 00 00 40 00 00 02 65 40
					39 00 00 40 00 00 21 D2 00 30 00 30 00 30 00 30 00 30 00 30 00 30 00 30 00 30 00 30 00 62 01 D4 01 D4 01 D4 01 D4 01 D4
					39 00 00 40 00 00 21 C9 00 05 00 0F 00 1E 00 2E 00 80 01 2E 02 61 05 4C 0A 29 13 E2 1A 5E 34 BC 3F FF 3F FF 3F FF 3F FF
					39 00 00 40 00 00 21 CD 00 05 00 0F 00 1E 00 2E 00 80 01 2E 02 61 05 4C 0A 29 13 E2 1A 5E 34 BC 3F FF 3F FF 3F FF 3F FF
					39 00 00 40 00 00 21 D1 00 05 00 0F 00 1E 00 2E 00 80 01 2E 02 61 05 4C 0A 29 13 E2 1A 5E 34 BC 3F FF 3F FF 3F FF 3F FF
					39 00 00 00 00 00 21 D5 00 05 00 0F 00 1E 00 2E 00 80 01 2E 02 61 05 4C 0A 29 13 E2 1A 5E 34 BC 3F FF 3F FF 3F FF 3F FF
					39 00 00 40 00 00 03 F0 AA 10
					39 00 00 40 00 00 02 65 04
					39 00 00 40 00 00 04 EA 48 CB 01
					39 00 00 40 00 00 02 65 0D
					39 00 00 40 00 00 04 EA 0C 00 01
					39 00 00 40 00 00 02 65 10
					39 00 00 40 00 00 04 EA 0C 80 01
					39 00 00 40 00 00 02 65 13
					39 00 00 40 00 00 04 EA C8 AE 01
					39 00 00 40 00 00 02 65 16
					39 00 00 40 00 00 04 EA 64 C1 01
					39 00 00 40 00 00 02 65 19
					39 00 00 40 00 00 04 EA 98 A5 01
					39 00 00 40 00 00 02 65 28
					39 00 00 40 00 00 04 EA 0C 00 00
					39 00 00 40 00 00 02 65 0A
					39 00 00 40 00 00 02 EB 10
					39 00 00 40 00 00 03 F0 AA 10
					39 00 00 40 00 00 02 65 01
					39 00 00 40 00 00 02 CF 87
					39 00 00 40 00 00 02 59 09
					39 00 00 40 00 00 03 F0 AA 10
					39 00 00 40 00 00 04 EB 00 00 30
					39 00 00 40 00 00 05 EA 0F 41 00 08
					39 00 00 40 00 00 03 F0 AA 11
					39 00 00 40 00 00 02 C3 00
					39 00 00 40 00 00 03 F0 AA 18
					39 00 00 40 00 00 02 B0 80
					39 00 00 40 00 00 03 F0 AA 19
					39 00 00 40 00 00 02 D0 01
					39 00 00 40 00 00 03 F0 AA 19
					39 00 00 40 00 00 02 C0 E0
					39 00 00 40 00 00 03 F0 AA 1A
					39 00 00 40 00 00 02 B0 01
					39 00 00 40 00 00 03 FF 5A 83
					39 00 00 40 00 00 02 65 0B
					39 00 00 40 00 00 02 F8 05
					39 00 00 40 00 00 03 FF 5A 81
					39 00 00 40 00 00 02 65 03
					39 00 00 40 00 00 02 F3 04
					39 00 00 40 00 00 02 65 05
					39 00 00 40 00 00 02 F3 48
					39 00 00 40 00 00 03 FF 5A 80
					39 00 00 40 00 00 02 65 0E
					39 00 00 40 00 00 02 F9 A1
					39 00 00 40 00 00 02 03 01
					39 00 00 40 00 00 02 35 00
					39 00 00 40 00 00 02 53 20
					39 00 00 40 00 00 03 51 00 00
					39 00 00 40 00 00 02 6B 00
					39 00 00 40 00 00 02 6F 02
					39 00 00 40 00 00 02 6C 01
					39 00 00 40 00 00 02 6D 00
					39 00 00 40 00 00 5F 70 12 00 00 AB 30 80 09 CE 04 84 00 0A 02 42 02 42 02 00 01 19 00 20 01 A0 00 08 00 01 00 E4 09 8D 18 00 11 00 07 10 20 00 06 0F 0F 33 0E 1C 2A 38 46 54 62 69 70 77 79 7B 7D 7E 02 02 22 00 2A 40 2A BE 3A FC 3A FA 3A F8 3B 38 3B 78 3B B6 4B B6 4B F4 4B F4 6C 34 84 74 00 00 00 00 00 00
					39 00 00 40 00 00 02 72 00
					39 00 00 40 00 00 03 F0 AA 00
					39 00 00 40 00 00 03 FF 5A 00
					39 00 00 40 00 00 03 FF 5A 80
					39 00 00 40 00 00 02 65 0E
					39 00 00 40 00 00 02 F9 A1
					39 00 00 00 78 00 01 11
					39 00 00 00 00 00 01 29
					//GIR & Slice ACL ON
					39 00 00 40 00 00 02 A4 01
					39 00 00 40 00 00 03 F0 AA 11
					39 00 00 40 00 00 02 D5 13
					39 00 00 40 00 00 02 C3 31
					39 00 00 40 00 00 02 A4 00
					39 00 00 00 00 00 02 A6 01
					//end
					//OSC sync to mipi clk begin
					39 00 00 40 00 00 03 F0 AA 14
					39 00 00 40 00 00 02 C1 0B
					39 00 00 40 00 00 20 C3 01 21 20 03 AD 03 AD 03 AD 03 AD 03 AD 03 AD 03 AD 00 C7 00 C7 00 C7 00 C7 00 31 00 31 00 31
					//end
					39 00 00 40 00 00 03 F0 AA 1E
					39 00 00 40 00 00 02 65 02
					39 00 00 00 00 00 02 C8 10
					39 00 00 40 00 00 03 F0 AA 10
					39 00 00 40 00 00 02 65 04
					39 00 00 40 00 00 02 B0 02
					//AOD timing optimization
					39 00 00 40 00 00 03 F0 AA 12
					39 00 00 40 00 00 02 65 02
					39 00 00 40 00 00 02 D1 00
					//MIPI Error Gating Set For ESD
					//check MIPI HS timeout
					39 00 00 40 00 00 03 F0 AA 10
					39 00 00 40 00 00 02 65 0B
					39 00 00 40 00 00 03 CF DD 79
					39 00 00 40 00 00 03 FF 5A 00
					39 00 00 00 00 00 03 F0 AA 00
					//AOD ISOP/IGOP/Pump clk
					39 00 00 40 00 00 03 F0 AA 10
					39 00 00 40 00 00 02 65 0A
					39 00 00 40 00 00 07 C4 00 00 00 00 00 00
					39 00 00 40 00 00 02 65 11
					39 00 00 40 00 00 02 C4 00
					39 00 00 40 00 00 03 F0 AA 12
					39 00 00 40 00 00 0C B2 75 35 77 75 35 77 75 35 77 57 05
					39 00 00 00 00 00 03 F0 AA 00
					//MIPI ULPS error ESD off
					39 00 00 40 00 00 03 F0 AA 10
					39 00 00 40 00 00 02 65 09
					39 00 00 40 00 00 02 CF 5B
					39 00 00 00 00 00 03 F0 AA 00
		        ];
				qcom,mdss-dsi-on-command-state = "dsi_lp_mode";
                 qcom,mdss-dsi-timing-switch-command = [
					//60hz
					39 00 00 00 00 00 02 6C 01
				];
				qcom,mdss-dsi-timing-switch-command-state = "dsi_hs_mode";
				mi,mdss-dsi-csc-by-temper-comp-off-mode-command = [
					39 00 00 40 00 00 03 F0 AA 1A
					39 00 00 40 00 00 02 B0 01
					39 00 00 00 00 00 02 6B 00
					39 00 00 00 00 00 03 F0 AA 00
				];
				mi,mdss-dsi-csc-by-temper-comp-off-mode-command-state = "dsi_hs_mode";
				mi,mdss-dsi-csc-by-temper-comp-32-36-mode-command = [
					39 00 00 40 00 00 03 F0 AA 1A
					39 00 00 40 00 00 02 B0 01
					39 00 00 00 00 00 02 6B 01
					39 00 00 00 00 00 03 F0 AA 00
				];
				mi,mdss-dsi-csc-by-temper-comp-32-36-mode-command-state = "dsi_hs_mode";
				mi,mdss-dsi-csc-by-temper-comp-36-40-mode-command = [
					39 00 00 40 00 00 03 F0 AA 1A
					39 00 00 40 00 00 02 B0 01
					39 00 00 00 00 00 02 6B 03
					39 00 00 00 00 00 03 F0 AA 00
				];
				mi,mdss-dsi-csc-by-temper-comp-36-40-mode-command-state = "dsi_hs_mode";
				mi,mdss-dsi-csc-by-temper-comp-40-mode-command = [
					39 00 00 40 00 00 03 F0 AA 1A
					39 00 00 40 00 00 02 B0 01
					39 00 00 00 00 00 02 6B 05
					39 00 00 00 00 00 03 F0 AA 00
				];
				mi,mdss-dsi-csc-by-temper-comp-40-mode-command-state = "dsi_hs_mode";
				mi,mdss-dsi-csc-by-temper-comp-45-mode-command = [
					39 00 00 40 00 00 03 F0 AA 1A
					39 00 00 40 00 00 02 B0 01
					39 00 00 00 00 00 02 6B 07
					39 00 00 00 00 00 03 F0 AA 00
				];
				mi,mdss-dsi-csc-by-temper-comp-45-mode-command-state = "dsi_hs_mode";
			};
		};
	};
};

&dsi_p11_42_0d_0a_p10_dsc_cmd {
	qcom,panel-supply-entries = <&dsi_panel_pwr_supply_p11>;
	qcom,mdss-dsi-bl-pmic-control-type = "bl_ctrl_dcs";
	qcom,mdss-dsi-bl-min-level = <5>;
	qcom,mdss-dsi-bl-max-level = <16383>;
	qcom,bl-dsc-cmd-state = "dsi_hs_mode";
	qcom,mdss-brightness-max-level = <16383>;
	qcom,mdss-brightness-init-level = <858>;
	qcom,platform-reset-gpio = <&tlmm 98 0>;
	mi,panel-build-id-read-needed;
	mi,panel-build-id-read-length = <1>;
	mi,mdss-dsi-panel-build-id-read-command = [06 01 00 01 00 00 01 DA];
	mi,mdss-dsi-panel-build-id-read-command-state = "dsi_hs_mode";

	qcom,mdss-dsi-panel-vsync-delay;
	qcom,ulps-enabled;
	qcom,dsi-select-clocks = "pll_byte_clk0", "pll_dsi_clk0";
	qcom,mdss-dsi-clk-strength = <0x88>;
};
